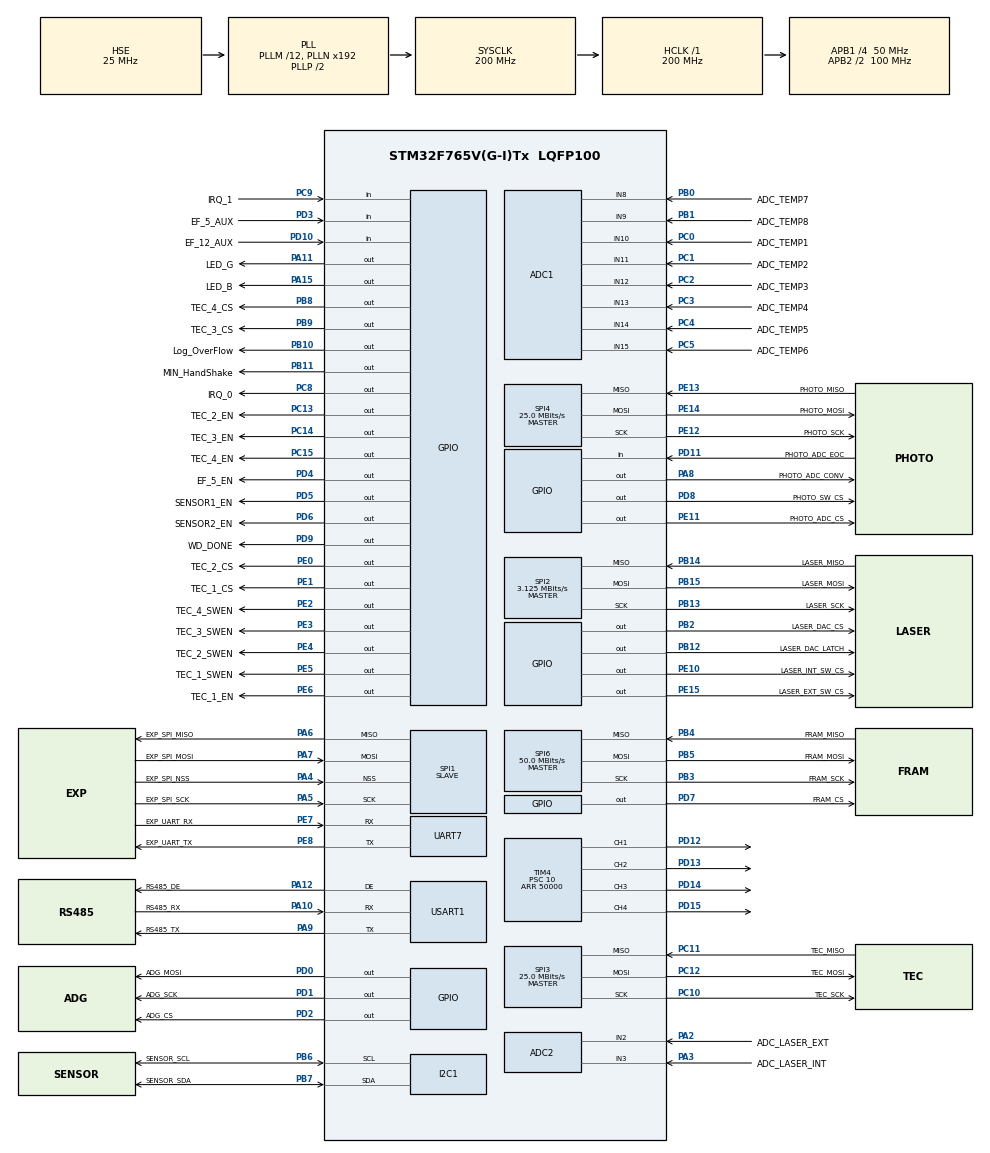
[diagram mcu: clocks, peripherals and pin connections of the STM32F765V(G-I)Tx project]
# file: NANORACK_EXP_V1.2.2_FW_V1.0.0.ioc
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ADC1.Channel-0\#ChannelRegularConversion=ADC_CHANNEL_10
ADC1.Channel-1\#ChannelRegularConversion=ADC_CHANNEL_11
ADC1.Channel-2\#ChannelRegularConversion=ADC_CHANNEL_12
ADC1.Channel-3\#ChannelRegularConversion=ADC_CHANNEL_13
ADC1.Channel-4\#ChannelRegularConversion=ADC_CHANNEL_14
ADC1.Channel-5\#ChannelRegularConversion=ADC_CHANNEL_15
ADC1.Channel-6\#ChannelRegularConversion=ADC_CHANNEL_8
ADC1.Channel-7\#ChannelRegularConversion=ADC_CHANNEL_9
ADC1.ContinuousConvMode=DISABLE
ADC1.DMAContinuousRequests=ENABLE
ADC1.EOCSelection=ADC_EOC_SEQ_CONV
ADC1.InjNumberOfConversion=0
ADC1.NbrOfConversion=8
ADC1.NbrOfConversionFlag=1
ADC1.Rank-0\#ChannelRegularConversion=1
ADC1.Rank-1\#ChannelRegularConversion=2
ADC1.Rank-2\#ChannelRegularConversion=3
ADC1.Rank-3\#ChannelRegularConversion=4
ADC1.Rank-4\#ChannelRegularConversion=5
ADC1.Rank-5\#ChannelRegularConversion=6
ADC1.Rank-6\#ChannelRegularConversion=7
ADC1.Rank-7\#ChannelRegularConversion=8
ADC1.SamplingTime-0\#ChannelRegularConversion=ADC_SAMPLETIME_15CYCLES
ADC1.SamplingTime-1\#ChannelRegularConversion=ADC_SAMPLETIME_15CYCLES
ADC1.SamplingTime-2\#ChannelRegularConversion=ADC_SAMPLETIME_15CYCLES
ADC1.SamplingTime-3\#ChannelRegularConversion=ADC_SAMPLETIME_15CYCLES
ADC1.SamplingTime-4\#ChannelRegularConversion=ADC_SAMPLETIME_15CYCLES
ADC1.SamplingTime-5\#ChannelRegularConversion=ADC_SAMPLETIME_15CYCLES
ADC1.SamplingTime-6\#ChannelRegularConversion=ADC_SAMPLETIME_15CYCLES
ADC1.SamplingTime-7\#ChannelRegularConversion=ADC_SAMPLETIME_15CYCLES
ADC1.master=1
ADC2.Channel-0\#ChannelRegularConversion=ADC_CHANNEL_3
ADC2.Channel-1\#ChannelRegularConversion=ADC_CHANNEL_2
ADC2.DMAContinuousRequests=ENABLE
ADC2.NbrOfConversion=2
ADC2.NbrOfConversionFlag=1
ADC2.Rank-0\#ChannelRegularConversion=1
ADC2.Rank-1\#ChannelRegularConversion=2
ADC2.SamplingTime-0\#ChannelRegularConversion=ADC_SAMPLETIME_15CYCLES
ADC2.SamplingTime-1\#ChannelRegularConversion=ADC_SAMPLETIME_3CYCLES
ADC2.ScanConvMode=ADC_SCAN_ENABLE
CORTEX_M7.MPU_Control=__NULL
CORTEX_M7.default_mode_Activation=1
Dma.ADC1.0.Direction=DMA_PERIPH_TO_MEMORY
Dma.ADC1.0.FIFOMode=DMA_FIFOMODE_DISABLE
Dma.ADC1.0.Instance=DMA2_Stream4
Dma.ADC1.0.MemDataAlignment=DMA_MDATAALIGN_HALFWORD
Dma.ADC1.0.MemInc=DMA_MINC_ENABLE
Dma.ADC1.0.Mode=DMA_CIRCULAR
Dma.ADC1.0.PeriphDataAlignment=DMA_PDATAALIGN_HALFWORD
Dma.ADC1.0.PeriphInc=DMA_PINC_DISABLE
Dma.ADC1.0.Priority=DMA_PRIORITY_LOW
Dma.ADC2.3.Direction=DMA_PERIPH_TO_MEMORY
Dma.ADC2.3.FIFOMode=DMA_FIFOMODE_DISABLE
Dma.ADC2.3.Instance=DMA2_Stream2
Dma.ADC2.3.MemDataAlignment=DMA_MDATAALIGN_HALFWORD
Dma.ADC2.3.MemInc=DMA_MINC_ENABLE
Dma.ADC2.3.Mode=DMA_CIRCULAR
Dma.ADC2.3.PeriphDataAlignment=DMA_PDATAALIGN_HALFWORD
Dma.ADC2.3.PeriphInc=DMA_PINC_DISABLE
Dma.ADC2.3.Priority=DMA_PRIORITY_LOW
Dma.Request0=ADC1
Dma.Request1=SPI6_TX
Dma.Request2=SPI6_RX
Dma.Request3=ADC2
Dma.Request4=SPI1_TX
Dma.Request5=SPI4_RX
Dma.SPI1_TX.4.Direction=DMA_MEMORY_TO_PERIPH
Dma.SPI1_TX.4.FIFOMode=DMA_FIFOMODE_DISABLE
Dma.SPI1_TX.4.Instance=DMA2_Stream3
Dma.SPI1_TX.4.MemDataAlignment=DMA_MDATAALIGN_BYTE
Dma.SPI1_TX.4.MemInc=DMA_MINC_ENABLE
Dma.SPI1_TX.4.Mode=DMA_NORMAL
Dma.SPI1_TX.4.PeriphDataAlignment=DMA_PDATAALIGN_BYTE
Dma.SPI1_TX.4.PeriphInc=DMA_PINC_DISABLE
Dma.SPI1_TX.4.Priority=DMA_PRIORITY_HIGH
Dma.SPI4_RX.5.Direction=DMA_PERIPH_TO_MEMORY
Dma.SPI4_RX.5.FIFOMode=DMA_FIFOMODE_DISABLE
Dma.SPI4_RX.5.Instance=DMA2_Stream0
Dma.SPI4_RX.5.MemDataAlignment=DMA_MDATAALIGN_HALFWORD
Dma.SPI4_RX.5.MemInc=DMA_MINC_ENABLE
Dma.SPI4_RX.5.Mode=DMA_CIRCULAR
Dma.SPI4_RX.5.PeriphDataAlignment=DMA_PDATAALIGN_HALFWORD
Dma.SPI4_RX.5.PeriphInc=DMA_PINC_DISABLE
Dma.SPI4_RX.5.Priority=DMA_PRIORITY_VERY_HIGH
Dma.SPI6_RX.2.Direction=DMA_PERIPH_TO_MEMORY
Dma.SPI6_RX.2.FIFOMode=DMA_FIFOMODE_DISABLE
Dma.SPI6_RX.2.Instance=DMA2_Stream6
Dma.SPI6_RX.2.MemDataAlignment=DMA_MDATAALIGN_BYTE
Dma.SPI6_RX.2.MemInc=DMA_MINC_ENABLE
Dma.SPI6_RX.2.Mode=DMA_NORMAL
Dma.SPI6_RX.2.PeriphDataAlignment=DMA_PDATAALIGN_BYTE
Dma.SPI6_RX.2.PeriphInc=DMA_PINC_DISABLE
Dma.SPI6_RX.2.Priority=DMA_PRIORITY_VERY_HIGH
Dma.SPI6_TX.1.Direction=DMA_MEMORY_TO_PERIPH
Dma.SPI6_TX.1.FIFOMode=DMA_FIFOMODE_DISABLE
Dma.SPI6_TX.1.Instance=DMA2_Stream5
Dma.SPI6_TX.1.MemDataAlignment=DMA_MDATAALIGN_BYTE
Dma.SPI6_TX.1.MemInc=DMA_MINC_ENABLE
Dma.SPI6_TX.1.Mode=DMA_NORMAL
Dma.SPI6_TX.1.PeriphDataAlignment=DMA_PDATAALIGN_BYTE
Dma.SPI6_TX.1.PeriphInc=DMA_PINC_DISABLE
Dma.SPI6_TX.1.Priority=DMA_PRIORITY_VERY_HIGH
I2C1.Speed=20
I2C1.Timing=0x601063FF
IWDG.Prescaler=IWDG_PRESCALER_128
IWDG.Reload=4000
IWDG.Window=4000
Mcu.Family=STM32F7
Mcu.Name=STM32F765V(G-I)Tx
Mcu.Package=LQFP100
NVIC.DMA2_Stream0_IRQn=true\:1\:0\:true\:false\:true\:false\:true\:true
NVIC.DMA2_Stream2_IRQn=true\:10\:0\:true\:false\:true\:false\:true\:true
NVIC.DMA2_Stream3_IRQn=true\:1\:0\:true\:false\:false\:false\:true\:true
NVIC.DMA2_Stream4_IRQn=true\:10\:0\:false\:false\:true\:false\:true\:true
NVIC.DMA2_Stream5_IRQn=true\:9\:0\:true\:false\:false\:false\:true\:true
NVIC.DMA2_Stream6_IRQn=true\:9\:0\:true\:false\:false\:false\:true\:true
NVIC.PriorityGroup=NVIC_PRIORITYGROUP_4
NVIC.TIM1_UP_TIM10_IRQn=true\:0\:0\:false\:false\:false\:true\:true\:true
NVIC.TIM2_IRQn=true\:2\:0\:true\:false\:false\:true\:true\:true
NVIC.UART7_IRQn=true\:11\:0\:true\:false\:false\:true\:true\:true
PA0/WKUP.Mode=SYS_WakeUp0
PA0/WKUP.Signal=SYS_WKUP1
PA1.GPIO_Label=ADC_TEC_OUT
PA1.Signal=ADCx_IN1
PA10.GPIO_Label=RS485_RX
PA10.Mode=Asynchronous
PA10.Signal=USART1_RX
PA11.GPIO_Label=LED_G
PA11.Signal=GPIO_Output
PA12.GPIO_Label=RS485_DE
PA12.Mode=Hardware Flow Control (RS485)
PA12.Signal=USART1_DE
PA13.Mode=Serial_Wire
PA13.Signal=SYS_JTMS-SWDIO
PA14.Mode=Serial_Wire
PA14.Signal=SYS_JTCK-SWCLK
PA15.GPIO_Label=LED_B
PA15.Signal=GPIO_Output
PA2.GPIO_Label=ADC_LASER_EXT
PA2.Signal=ADCx_IN2
PA3.GPIO_Label=ADC_LASER_INT
PA3.Signal=ADCx_IN3
PA4.GPIO_Label=EXP_SPI_NSS
PA4.Mode=NSS_Signal_Hard_Input
PA4.Signal=SPI1_NSS
PA5.GPIO_Label=EXP_SPI_SCK
PA5.Mode=Full_Duplex_Slave
PA5.Signal=SPI1_SCK
PA6.GPIO_Label=EXP_SPI_MISO
PA6.Mode=Full_Duplex_Slave
PA6.Signal=SPI1_MISO
PA7.GPIO_Label=EXP_SPI_MOSI
PA7.Mode=Full_Duplex_Slave
PA7.Signal=SPI1_MOSI
PA8.GPIO_Label=PHOTO_ADC_CONV
PA8.GPIO_Speed=GPIO_SPEED_FREQ_VERY_HIGH
PA8.PinState=GPIO_PIN_SET
PA8.Signal=GPIO_Output
PA9.GPIO_Label=RS485_TX
PA9.Mode=Asynchronous
PA9.Signal=USART1_TX
PB0.GPIO_Label=ADC_TEMP7
PB0.Signal=ADCx_IN8
PB1.GPIO_Label=ADC_TEMP8
PB1.Signal=ADCx_IN9
PB10.GPIO_Label=Log_OverFlow
PB10.GPIO_PuPd=GPIO_PULLUP
PB10.PinState=GPIO_PIN_SET
PB10.Signal=GPIO_Output
PB11.GPIO_Label=MIN_HandShake
PB11.GPIO_PuPd=GPIO_PULLDOWN
PB11.Signal=GPIO_Output
PB12.GPIO_Label=LASER_DAC_LATCH
PB12.PinState=GPIO_PIN_SET
PB12.Signal=GPIO_Output
PB13.GPIO_Label=LASER_SCK
PB13.Mode=Full_Duplex_Master
PB13.Signal=SPI2_SCK
PB14.GPIO_Label=LASER_MISO
PB14.Mode=Full_Duplex_Master
PB14.Signal=SPI2_MISO
PB15.GPIO_Label=LASER_MOSI
PB15.Mode=Full_Duplex_Master
PB15.Signal=SPI2_MOSI
PB2.GPIO_Label=LASER_DAC_CS
PB2.PinState=GPIO_PIN_SET
PB2.Signal=GPIO_Output
PB3.GPIO_Label=FRAM_SCK
PB3.Mode=Full_Duplex_Master
PB3.Signal=SPI6_SCK
PB4.GPIO_Label=FRAM_MISO
PB4.Mode=Full_Duplex_Master
PB4.Signal=SPI6_MISO
PB5.GPIO_Label=FRAM_MOSI
PB5.Mode=Full_Duplex_Master
PB5.Signal=SPI6_MOSI
PB6.GPIO_Label=SENSOR_SCL
PB6.Mode=I2C
PB6.Signal=I2C1_SCL
PB7.GPIO_Label=SENSOR_SDA
PB7.Mode=I2C
PB7.Signal=I2C1_SDA
PB8.GPIO_Label=TEC_4_CS
PB8.PinState=GPIO_PIN_SET
PB8.Signal=GPIO_Output
PB9.GPIO_Label=TEC_3_CS
PB9.PinState=GPIO_PIN_SET
PB9.Signal=GPIO_Output
PC0.GPIO_Label=ADC_TEMP1
PC0.Signal=ADCx_IN10
PC1.GPIO_Label=ADC_TEMP2
PC1.Signal=ADCx_IN11
PC10.GPIO_Label=TEC_SCK
PC10.Mode=Full_Duplex_Master
PC10.Signal=SPI3_SCK
PC11.GPIO_Label=TEC_MISO
PC11.Mode=Full_Duplex_Master
PC11.Signal=SPI3_MISO
PC12.GPIO_Label=TEC_MOSI
PC12.Mode=Full_Duplex_Master
PC12.Signal=SPI3_MOSI
PC13.GPIO_Label=TEC_2_EN
PC13.Signal=GPIO_Output
PC14/OSC32_IN.GPIO_Label=TEC_3_EN
PC14/OSC32_IN.Signal=GPIO_Output
PC15/OSC32_OUT.GPIO_Label=TEC_4_EN
PC15/OSC32_OUT.Signal=GPIO_Output
PC2.GPIO_Label=ADC_TEMP3
PC2.Signal=ADCx_IN12
PC3.GPIO_Label=ADC_TEMP4
PC3.Signal=ADCx_IN13
PC4.GPIO_Label=ADC_TEMP5
PC4.Signal=ADCx_IN14
PC5.GPIO_Label=ADC_TEMP6
PC5.Signal=ADCx_IN15
PC6.GPIO_Label=CONS_TX
PC6.Signal=USART6_TX
PC7.GPIO_Label=CONS_RX
PC7.Signal=USART6_RX
PC8.GPIO_Label=IRQ_0
PC8.GPIO_PuPd=GPIO_PULLUP
PC8.PinState=GPIO_PIN_SET
PC8.Signal=GPIO_Output
PC9.GPIO_Label=IRQ_1
PC9.Signal=GPIO_Input
PD0.GPIO_Label=ADG_MOSI
PD0.Signal=GPIO_Output
PD1.GPIO_Label=ADG_SCK
PD1.Signal=GPIO_Output
PD10.GPIO_Label=EF_12_AUX
PD10.Signal=GPIO_Input
PD11.GPIO_Label=PHOTO_ADC_EOC
PD11.Signal=GPIO_Input
PD12.Signal=S_TIM4_CH1
PD13.Signal=S_TIM4_CH2
PD14.Signal=S_TIM4_CH3
PD15.Signal=S_TIM4_CH4
PD2.GPIO_Label=ADG_CS
PD2.PinState=GPIO_PIN_SET
PD2.Signal=GPIO_Output
PD3.GPIO_Label=EF_5_AUX
PD3.Signal=GPIO_Input
PD4.GPIO_Label=EF_5_EN
PD4.Signal=GPIO_Output
PD5.GPIO_Label=SENSOR1_EN
PD5.Signal=GPIO_Output
PD6.GPIO_Label=SENSOR2_EN
PD6.Signal=GPIO_Output
PD7.GPIO_Label=FRAM_CS
PD7.PinState=GPIO_PIN_SET
PD7.Signal=GPIO_Output
PD8.GPIO_Label=PHOTO_SW_CS
PD8.GPIO_Speed=GPIO_SPEED_FREQ_VERY_HIGH
PD8.PinState=GPIO_PIN_SET
PD8.Signal=GPIO_Output
PD9.GPIO_Label=WD_DONE
PD9.GPIO_Speed=GPIO_SPEED_FREQ_VERY_HIGH
PD9.PinState=GPIO_PIN_SET
PD9.Signal=GPIO_Output
PE0.GPIO_Label=TEC_2_CS
PE0.PinState=GPIO_PIN_SET
PE0.Signal=GPIO_Output
PE1.GPIO_Label=TEC_1_CS
PE1.PinState=GPIO_PIN_SET
PE1.Signal=GPIO_Output
PE10.GPIO_Label=LASER_INT_SW_CS
PE10.PinState=GPIO_PIN_SET
PE10.Signal=GPIO_Output
PE11.GPIO_Label=PHOTO_ADC_CS
PE11.GPIO_Speed=GPIO_SPEED_FREQ_LOW
PE11.PinState=GPIO_PIN_SET
PE11.Signal=GPIO_Output
PE12.GPIO_Label=PHOTO_SCK
PE12.Mode=Full_Duplex_Master
PE12.Signal=SPI4_SCK
PE13.GPIO_Label=PHOTO_MISO
PE13.Mode=Full_Duplex_Master
PE13.Signal=SPI4_MISO
PE14.GPIO_Label=PHOTO_MOSI
PE14.Mode=Full_Duplex_Master
PE14.Signal=SPI4_MOSI
PE15.GPIO_Label=LASER_EXT_SW_CS
PE15.PinState=GPIO_PIN_SET
PE15.Signal=GPIO_Output
PE2.GPIO_Label=TEC_4_SWEN
PE2.Signal=GPIO_Output
PE3.GPIO_Label=TEC_3_SWEN
PE3.Signal=GPIO_Output
PE4.GPIO_Label=TEC_2_SWEN
PE4.Signal=GPIO_Output
PE5.GPIO_Label=TEC_1_SWEN
PE5.Signal=GPIO_Output
PE6.GPIO_Label=TEC_1_EN
PE6.Signal=GPIO_Output
PE7.GPIO_Label=EXP_UART_RX
PE7.GPIO_PuPd=GPIO_PULLUP
PE7.Mode=Asynchronous
PE7.Signal=UART7_RX
PE8.GPIO_Label=EXP_UART_TX
PE8.Mode=Asynchronous
PE8.Signal=UART7_TX
PH0/OSC_IN.Mode=HSE-External-Oscillator
PH0/OSC_IN.Signal=RCC_OSC_IN
PH1/OSC_OUT.Mode=HSE-External-Oscillator
PH1/OSC_OUT.Signal=RCC_OSC_OUT
ProjectManager.HeapSize=0x200
ProjectManager.StackSize=0x400
ProjectManager.TargetToolchain=STM32CubeIDE
RCC.AHBFreq_Value=200000000
RCC.APB1CLKDivider=RCC_HCLK_DIV4
RCC.APB1Freq_Value=50000000
RCC.APB1TimFreq_Value=100000000
RCC.APB2CLKDivider=RCC_HCLK_DIV2
RCC.APB2Freq_Value=100000000
RCC.APB2TimFreq_Value=200000000
RCC.CortexFreq_Value=200000000
RCC.HCLKFreq_Value=200000000
RCC.HSE_VALUE=25000000
RCC.HSI_VALUE=16000000
RCC.LSE_VALUE=32768
RCC.PLLM=12
RCC.PLLSourceVirtual=RCC_PLLSOURCE_HSE
RCC.SYSCLKFreq_VALUE=200000000
RCC.SYSCLKSource=RCC_SYSCLKSOURCE_PLLCLK
RCC.USBFreq_Value=200000000
RCC.VCOOutputFreq_Value=400000000
SH.ADCx_IN1.0=ADC3_IN1
SH.ADCx_IN10.0=ADC1_IN10,IN10
SH.ADCx_IN11.0=ADC1_IN11,IN11
SH.ADCx_IN12.0=ADC1_IN12,IN12
SH.ADCx_IN13.0=ADC1_IN13,IN13
SH.ADCx_IN14.0=ADC1_IN14,IN14
SH.ADCx_IN15.0=ADC1_IN15,IN15
SH.ADCx_IN2.0=ADC2_IN2,IN2
SH.ADCx_IN3.0=ADC2_IN3,IN3
SH.ADCx_IN8.0=ADC1_IN8,IN8
SH.ADCx_IN9.0=ADC1_IN9,IN9
SH.S_TIM4_CH1.0=TIM4_CH1,PWM Generation1 CH1
SH.S_TIM4_CH2.0=TIM4_CH2,PWM Generation2 CH2
SH.S_TIM4_CH3.0=TIM4_CH3,PWM Generation3 CH3
SH.S_TIM4_CH4.0=TIM4_CH4,PWM Generation4 CH4
SPI1.CLKPolarity=SPI_POLARITY_HIGH
SPI1.DataSize=SPI_DATASIZE_8BIT
SPI1.Direction=SPI_DIRECTION_2LINES
SPI1.Mode=SPI_MODE_SLAVE
SPI1.VirtualNSS=VM_NSSHARD
SPI1.VirtualType=VM_SLAVE
SPI2.BaudRatePrescaler=SPI_BAUDRATEPRESCALER_16
SPI2.CLKPhase=SPI_PHASE_2EDGE
SPI2.CalculateBaudRate=3.125 MBits/s
SPI2.DataSize=SPI_DATASIZE_8BIT
SPI2.Direction=SPI_DIRECTION_2LINES
SPI2.Mode=SPI_MODE_MASTER
SPI2.VirtualType=VM_MASTER
SPI3.BaudRatePrescaler=SPI_BAUDRATEPRESCALER_2
SPI3.CalculateBaudRate=25.0 MBits/s
SPI3.DataSize=SPI_DATASIZE_8BIT
SPI3.Direction=SPI_DIRECTION_2LINES
SPI3.Mode=SPI_MODE_MASTER
SPI3.VirtualType=VM_MASTER
SPI4.BaudRatePrescaler=SPI_BAUDRATEPRESCALER_4
SPI4.CLKPhase=SPI_PHASE_1EDGE
SPI4.CalculateBaudRate=25.0 MBits/s
SPI4.DataSize=SPI_DATASIZE_16BIT
SPI4.Direction=SPI_DIRECTION_2LINES
SPI4.Mode=SPI_MODE_MASTER
SPI4.VirtualType=VM_MASTER
SPI6.BaudRatePrescaler=SPI_BAUDRATEPRESCALER_2
SPI6.CalculateBaudRate=50.0 MBits/s
SPI6.DataSize=SPI_DATASIZE_8BIT
SPI6.Direction=SPI_DIRECTION_2LINES
SPI6.Mode=SPI_MODE_MASTER
SPI6.VirtualType=VM_MASTER
TIM1.Prescaler=0
TIM2.AutoReloadPreload=TIM_AUTORELOAD_PRELOAD_ENABLE
TIM4.Channel-PWM\ Generation1\ CH1=TIM_CHANNEL_1
TIM4.Channel-PWM\ Generation2\ CH2=TIM_CHANNEL_2
TIM4.Channel-PWM\ Generation3\ CH3=TIM_CHANNEL_3
TIM4.Channel-PWM\ Generation4\ CH4=TIM_CHANNEL_4
TIM4.ClockDivision=TIM_CLOCKDIVISION_DIV4
TIM4.Period=50000
TIM4.Prescaler=10
USART1.VirtualMode-Asynchronous=VM_ASYNC
USART1.VirtualMode-Hardware\ Flow\ Control\ (RS485)=VM_ASYNC
VP_CRC_VS_CRC.Mode=CRC_Activate
VP_IWDG_VS_IWDG.Mode=IWDG_Activate
VP_TIM1_VS_ClockSourceINT.Mode=Internal
VP_TIM2_VS_ClockSourceINT.Mode=Internal
VP_TIM4_VS_ClockSourceINT.Mode=Internal
board=custom

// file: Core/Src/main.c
/* USER CODE BEGIN Header */
/**
  ******************************************************************************
  * @file           : main.c
  * @brief          : Main program body
  ******************************************************************************
  * @attention
  *
  * Copyright (c) 2025 STMicroelectronics.
  * All rights reserved.
  *
  * This software is licensed under terms that can be found in the LICENSE file
  * in the root directory of this software component.
  * If no LICENSE file comes with this software, it is provided AS-IS.
  *
  ******************************************************************************
  */
/* USER CODE END Header */
#include "main.h"

/* USER CODE BEGIN Includes */
#include "board.h"
#include "uart_driver.h"
#include "ntc.h"
#include "cli_command.h"
#include "sensor_i2c.h"
#include "adg1414.h"
#include "ads8327.h"
#include "mcp4902.h"
#include "app_main.h"
#include "bsp_photodiode.h"
#include "bsp_spi_ram.h"
#include "IS66WVS4M8BLL.h"
/* USER CODE END Includes */

CRC_HandleTypeDef hcrc;

void SystemClock_Config(void);
static void MX_GPIO_Init(void);
static void MX_DMA_Init(void);
static void MX_I2C1_Init(void);
static void MX_SPI1_Init(void);
static void MX_SPI2_Init(void);
static void MX_SPI3_Init(void);
static void MX_ADC1_Init(void);
static void MX_SPI4_Init(void);
static void MX_TIM4_Init(void);
static void MX_UART7_Init(void);
static void MX_SPI6_Init(void);
static void MX_USART1_UART_Init(void);
static void MX_ADC2_Init(void);
static void MX_TIM1_Init(void);
static void MX_TIM2_Init(void);
static void MX_IWDG_Init(void);
static void MX_CRC_Init(void);
/* USER CODE BEGIN PFP */
void SPI1_ReInit(void)
{
	MX_SPI1_Init();
}
/* USER CODE END PFP */

int main(void)
{

  /* MCU Configuration--------------------------------------------------------*/

  /* Reset of all peripherals, Initializes the Flash interface and the Systick. */
  HAL_Init();

  /* Configure the system clock */
  SystemClock_Config();

  /* Initialize all configured peripherals */
  MX_GPIO_Init();
  MX_DMA_Init();
  MX_I2C1_Init();
  MX_SPI1_Init();
  MX_SPI2_Init();
  MX_SPI3_Init();
  MX_ADC1_Init();
  MX_SPI4_Init();
  MX_TIM4_Init();
  MX_UART7_Init();
  MX_SPI6_Init();
  MX_USART1_UART_Init();
  MX_ADC2_Init();
  MX_TIM1_Init();
  MX_TIM2_Init();
  MX_IWDG_Init();
  MX_CRC_Init();

  /* Infinite loop */
  /* USER CODE BEGIN WHILE */

  app_init();
  app_start();
  app_run();
  while (1)
  {
    /* USER CODE END WHILE */

  }
}

void SystemClock_Config(void)
{
  RCC_OscInitTypeDef RCC_OscInitStruct = {0};
  RCC_ClkInitTypeDef RCC_ClkInitStruct = {0};

  /** Configure the main internal regulator output voltage
  */
  __HAL_RCC_PWR_CLK_ENABLE();
  __HAL_PWR_VOLTAGESCALING_CONFIG(PWR_REGULATOR_VOLTAGE_SCALE1);

  /** Initializes the RCC Oscillators according to the specified parameters
  * in the RCC_OscInitTypeDef structure.
  */
  RCC_OscInitStruct.OscillatorType = RCC_OSCILLATORTYPE_LSI|RCC_OSCILLATORTYPE_HSE;
  RCC_OscInitStruct.HSEState = RCC_HSE_ON;
  RCC_OscInitStruct.LSIState = RCC_LSI_ON;
  RCC_OscInitStruct.PLL.PLLState = RCC_PLL_ON;
  RCC_OscInitStruct.PLL.PLLSource = RCC_PLLSOURCE_HSE;
  RCC_OscInitStruct.PLL.PLLM = 12;
  RCC_OscInitStruct.PLL.PLLN = 192;
  RCC_OscInitStruct.PLL.PLLP = RCC_PLLP_DIV2;
  RCC_OscInitStruct.PLL.PLLQ = 2;
  RCC_OscInitStruct.PLL.PLLR = 2;
  if (HAL_RCC_OscConfig(&RCC_OscInitStruct) != HAL_OK)
  {
    Error_Handler();
  }

  /** Activate the Over-Drive mode
  */
  if (HAL_PWREx_EnableOverDrive() != HAL_OK)
  {
    Error_Handler();
  }

  /** Initializes the CPU, AHB and APB buses clocks
  */
  RCC_ClkInitStruct.ClockType = RCC_CLOCKTYPE_HCLK|RCC_CLOCKTYPE_SYSCLK
                              |RCC_CLOCKTYPE_PCLK1|RCC_CLOCKTYPE_PCLK2;
  RCC_ClkInitStruct.SYSCLKSource = RCC_SYSCLKSOURCE_PLLCLK;
  RCC_ClkInitStruct.AHBCLKDivider = RCC_SYSCLK_DIV1;
  RCC_ClkInitStruct.APB1CLKDivider = RCC_HCLK_DIV4;
  RCC_ClkInitStruct.APB2CLKDivider = RCC_HCLK_DIV2;

  if (HAL_RCC_ClockConfig(&RCC_ClkInitStruct, FLASH_LATENCY_6) != HAL_OK)
  {
    Error_Handler();
  }
}

static void MX_ADC1_Init(void)
{

  LL_ADC_InitTypeDef ADC_InitStruct = {0};
  LL_ADC_REG_InitTypeDef ADC_REG_InitStruct = {0};
  LL_ADC_CommonInitTypeDef ADC_CommonInitStruct = {0};

  LL_GPIO_InitTypeDef GPIO_InitStruct = {0};

  /* Peripheral clock enable */
  LL_APB2_GRP1_EnableClock(LL_APB2_GRP1_PERIPH_ADC1);

  LL_AHB1_GRP1_EnableClock(LL_AHB1_GRP1_PERIPH_GPIOC);
  LL_AHB1_GRP1_EnableClock(LL_AHB1_GRP1_PERIPH_GPIOB);
  /**ADC1 GPIO Configuration
  PC0   ------> ADC1_IN10
  PC1   ------> ADC1_IN11
  PC2   ------> ADC1_IN12
  PC3   ------> ADC1_IN13
  PC4   ------> ADC1_IN14
  PC5   ------> ADC1_IN15
  PB0   ------> ADC1_IN8
  PB1   ------> ADC1_IN9
  */
  GPIO_InitStruct.Pin = ADC_TEMP1_Pin;
  GPIO_InitStruct.Mode = LL_GPIO_MODE_ANALOG;
  GPIO_InitStruct.Pull = LL_GPIO_PULL_NO;
  LL_GPIO_Init(ADC_TEMP1_GPIO_Port, &GPIO_InitStruct);

  GPIO_InitStruct.Pin = ADC_TEMP2_Pin;
  GPIO_InitStruct.Mode = LL_GPIO_MODE_ANALOG;
  GPIO_InitStruct.Pull = LL_GPIO_PULL_NO;
  LL_GPIO_Init(ADC_TEMP2_GPIO_Port, &GPIO_InitStruct);

  GPIO_InitStruct.Pin = ADC_TEMP3_Pin;
  GPIO_InitStruct.Mode = LL_GPIO_MODE_ANALOG;
  GPIO_InitStruct.Pull = LL_GPIO_PULL_NO;
  LL_GPIO_Init(ADC_TEMP3_GPIO_Port, &GPIO_InitStruct);

  GPIO_InitStruct.Pin = ADC_TEMP4_Pin;
  GPIO_InitStruct.Mode = LL_GPIO_MODE_ANALOG;
  GPIO_InitStruct.Pull = LL_GPIO_PULL_NO;
  LL_GPIO_Init(ADC_TEMP4_GPIO_Port, &GPIO_InitStruct);

  GPIO_InitStruct.Pin = ADC_TEMP5_Pin;
  GPIO_InitStruct.Mode = LL_GPIO_MODE_ANALOG;
  GPIO_InitStruct.Pull = LL_GPIO_PULL_NO;
  LL_GPIO_Init(ADC_TEMP5_GPIO_Port, &GPIO_InitStruct);

  GPIO_InitStruct.Pin = ADC_TEMP6_Pin;
  GPIO_InitStruct.Mode = LL_GPIO_MODE_ANALOG;
  GPIO_InitStruct.Pull = LL_GPIO_PULL_NO;
  LL_GPIO_Init(ADC_TEMP6_GPIO_Port, &GPIO_InitStruct);

  GPIO_InitStruct.Pin = ADC_TEMP7_Pin;
  GPIO_InitStruct.Mode = LL_GPIO_MODE_ANALOG;
  GPIO_InitStruct.Pull = LL_GPIO_PULL_NO;
  LL_GPIO_Init(ADC_TEMP7_GPIO_Port, &GPIO_InitStruct);

  GPIO_InitStruct.Pin = ADC_TEMP8_Pin;
  GPIO_InitStruct.Mode = LL_GPIO_MODE_ANALOG;
  GPIO_InitStruct.Pull = LL_GPIO_PULL_NO;
  LL_GPIO_Init(ADC_TEMP8_GPIO_Port, &GPIO_InitStruct);

  /* ADC1 DMA Init */

  /* ADC1 Init */
  LL_DMA_SetChannelSelection(DMA2, LL_DMA_STREAM_4, LL_DMA_CHANNEL_0);

  LL_DMA_SetDataTransferDirection(DMA2, LL_DMA_STREAM_4, LL_DMA_DIRECTION_PERIPH_TO_MEMORY);

  LL_DMA_SetStreamPriorityLevel(DMA2, LL_DMA_STREAM_4, LL_DMA_PRIORITY_LOW);

  LL_DMA_SetMode(DMA2, LL_DMA_STREAM_4, LL_DMA_MODE_CIRCULAR);

  LL_DMA_SetPeriphIncMode(DMA2, LL_DMA_STREAM_4, LL_DMA_PERIPH_NOINCREMENT);

  LL_DMA_SetMemoryIncMode(DMA2, LL_DMA_STREAM_4, LL_DMA_MEMORY_INCREMENT);

  LL_DMA_SetPeriphSize(DMA2, LL_DMA_STREAM_4, LL_DMA_PDATAALIGN_HALFWORD);

  LL_DMA_SetMemorySize(DMA2, LL_DMA_STREAM_4, LL_DMA_MDATAALIGN_HALFWORD);

  LL_DMA_DisableFifoMode(DMA2, LL_DMA_STREAM_4);

  /** Common config
  */
  ADC_InitStruct.Resolution = LL_ADC_RESOLUTION_12B;
  ADC_InitStruct.DataAlignment = LL_ADC_DATA_ALIGN_RIGHT;
  ADC_InitStruct.SequencersScanMode = LL_ADC_SEQ_SCAN_ENABLE;
  LL_ADC_Init(ADC1, &ADC_InitStruct);
  ADC_REG_InitStruct.TriggerSource = LL_ADC_REG_TRIG_SOFTWARE;
  ADC_REG_InitStruct.SequencerLength = LL_ADC_REG_SEQ_SCAN_ENABLE_8RANKS;
  ADC_REG_InitStruct.SequencerDiscont = LL_ADC_REG_SEQ_DISCONT_DISABLE;
  ADC_REG_InitStruct.ContinuousMode = LL_ADC_REG_CONV_SINGLE;
  ADC_REG_InitStruct.DMATransfer = LL_ADC_REG_DMA_TRANSFER_UNLIMITED;
  LL_ADC_REG_Init(ADC1, &ADC_REG_InitStruct);
  LL_ADC_REG_SetFlagEndOfConversion(ADC1, LL_ADC_REG_FLAG_EOC_SEQUENCE_CONV);
  ADC_CommonInitStruct.CommonClock = LL_ADC_CLOCK_SYNC_PCLK_DIV4;
  ADC_CommonInitStruct.Multimode = LL_ADC_MULTI_INDEPENDENT;
  LL_ADC_CommonInit(__LL_ADC_COMMON_INSTANCE(ADC1), &ADC_CommonInitStruct);

  /** Configure Regular Channel
  */
  LL_ADC_REG_SetSequencerRanks(ADC1, LL_ADC_REG_RANK_1, LL_ADC_CHANNEL_10);
  LL_ADC_SetChannelSamplingTime(ADC1, LL_ADC_CHANNEL_10, LL_ADC_SAMPLINGTIME_15CYCLES);

  /** Configure Regular Channel
  */
  LL_ADC_REG_SetSequencerRanks(ADC1, LL_ADC_REG_RANK_2, LL_ADC_CHANNEL_11);
  LL_ADC_SetChannelSamplingTime(ADC1, LL_ADC_CHANNEL_11, LL_ADC_SAMPLINGTIME_15CYCLES);

  /** Configure Regular Channel
  */
  LL_ADC_REG_SetSequencerRanks(ADC1, LL_ADC_REG_RANK_3, LL_ADC_CHANNEL_12);
  LL_ADC_SetChannelSamplingTime(ADC1, LL_ADC_CHANNEL_12, LL_ADC_SAMPLINGTIME_15CYCLES);

  /** Configure Regular Channel
  */
  LL_ADC_REG_SetSequencerRanks(ADC1, LL_ADC_REG_RANK_4, LL_ADC_CHANNEL_13);
  LL_ADC_SetChannelSamplingTime(ADC1, LL_ADC_CHANNEL_13, LL_ADC_SAMPLINGTIME_15CYCLES);

  /** Configure Regular Channel
  */
  LL_ADC_REG_SetSequencerRanks(ADC1, LL_ADC_REG_RANK_5, LL_ADC_CHANNEL_14);
  LL_ADC_SetChannelSamplingTime(ADC1, LL_ADC_CHANNEL_14, LL_ADC_SAMPLINGTIME_15CYCLES);

  /** Configure Regular Channel
  */
  LL_ADC_REG_SetSequencerRanks(ADC1, LL_ADC_REG_RANK_6, LL_ADC_CHANNEL_15);
  LL_ADC_SetChannelSamplingTime(ADC1, LL_ADC_CHANNEL_15, LL_ADC_SAMPLINGTIME_15CYCLES);

  /** Configure Regular Channel
  */
  LL_ADC_REG_SetSequencerRanks(ADC1, LL_ADC_REG_RANK_7, LL_ADC_CHANNEL_8);
  LL_ADC_SetChannelSamplingTime(ADC1, LL_ADC_CHANNEL_8, LL_ADC_SAMPLINGTIME_15CYCLES);

  /** Configure Regular Channel
  */
  LL_ADC_REG_SetSequencerRanks(ADC1, LL_ADC_REG_RANK_8, LL_ADC_CHANNEL_9);
  LL_ADC_SetChannelSamplingTime(ADC1, LL_ADC_CHANNEL_9, LL_ADC_SAMPLINGTIME_15CYCLES);

}

static void MX_ADC2_Init(void)
{

  LL_ADC_InitTypeDef ADC_InitStruct = {0};
  LL_ADC_REG_InitTypeDef ADC_REG_InitStruct = {0};

  LL_GPIO_InitTypeDef GPIO_InitStruct = {0};

  /* Peripheral clock enable */
  LL_APB2_GRP1_EnableClock(LL_APB2_GRP1_PERIPH_ADC2);

  LL_AHB1_GRP1_EnableClock(LL_AHB1_GRP1_PERIPH_GPIOA);
  /**ADC2 GPIO Configuration
  PA2   ------> ADC2_IN2
  PA3   ------> ADC2_IN3
  */
  GPIO_InitStruct.Pin = ADC_LASER_EXT_Pin;
  GPIO_InitStruct.Mode = LL_GPIO_MODE_ANALOG;
  GPIO_InitStruct.Pull = LL_GPIO_PULL_NO;
  LL_GPIO_Init(ADC_LASER_EXT_GPIO_Port, &GPIO_InitStruct);

  GPIO_InitStruct.Pin = ADC_LASER_INT_Pin;
  GPIO_InitStruct.Mode = LL_GPIO_MODE_ANALOG;
  GPIO_InitStruct.Pull = LL_GPIO_PULL_NO;
  LL_GPIO_Init(ADC_LASER_INT_GPIO_Port, &GPIO_InitStruct);

  /* ADC2 DMA Init */

  /* ADC2 Init */
  LL_DMA_SetChannelSelection(DMA2, LL_DMA_STREAM_2, LL_DMA_CHANNEL_1);

  LL_DMA_SetDataTransferDirection(DMA2, LL_DMA_STREAM_2, LL_DMA_DIRECTION_PERIPH_TO_MEMORY);

  LL_DMA_SetStreamPriorityLevel(DMA2, LL_DMA_STREAM_2, LL_DMA_PRIORITY_LOW);

  LL_DMA_SetMode(DMA2, LL_DMA_STREAM_2, LL_DMA_MODE_CIRCULAR);

  LL_DMA_SetPeriphIncMode(DMA2, LL_DMA_STREAM_2, LL_DMA_PERIPH_NOINCREMENT);

  LL_DMA_SetMemoryIncMode(DMA2, LL_DMA_STREAM_2, LL_DMA_MEMORY_INCREMENT);

  LL_DMA_SetPeriphSize(DMA2, LL_DMA_STREAM_2, LL_DMA_PDATAALIGN_HALFWORD);

  LL_DMA_SetMemorySize(DMA2, LL_DMA_STREAM_2, LL_DMA_MDATAALIGN_HALFWORD);

  LL_DMA_DisableFifoMode(DMA2, LL_DMA_STREAM_2);

  /** Common config
  */
  ADC_InitStruct.Resolution = LL_ADC_RESOLUTION_12B;
  ADC_InitStruct.DataAlignment = LL_ADC_DATA_ALIGN_RIGHT;
  ADC_InitStruct.SequencersScanMode = LL_ADC_SEQ_SCAN_ENABLE;
  LL_ADC_Init(ADC2, &ADC_InitStruct);
  ADC_REG_InitStruct.TriggerSource = LL_ADC_REG_TRIG_SOFTWARE;
  ADC_REG_InitStruct.SequencerLength = LL_ADC_REG_SEQ_SCAN_ENABLE_2RANKS;
  ADC_REG_InitStruct.SequencerDiscont = LL_ADC_REG_SEQ_DISCONT_DISABLE;
  ADC_REG_InitStruct.ContinuousMode = LL_ADC_REG_CONV_SINGLE;
  ADC_REG_InitStruct.DMATransfer = LL_ADC_REG_DMA_TRANSFER_UNLIMITED;
  LL_ADC_REG_Init(ADC2, &ADC_REG_InitStruct);
  LL_ADC_REG_SetFlagEndOfConversion(ADC2, LL_ADC_REG_FLAG_EOC_UNITARY_CONV);

  /** Configure Regular Channel
  */
  LL_ADC_REG_SetSequencerRanks(ADC2, LL_ADC_REG_RANK_1, LL_ADC_CHANNEL_3);
  LL_ADC_SetChannelSamplingTime(ADC2, LL_ADC_CHANNEL_3, LL_ADC_SAMPLINGTIME_15CYCLES);

  /** Configure Regular Channel
  */
  LL_ADC_REG_SetSequencerRanks(ADC2, LL_ADC_REG_RANK_2, LL_ADC_CHANNEL_2);
  LL_ADC_SetChannelSamplingTime(ADC2, LL_ADC_CHANNEL_2, LL_ADC_SAMPLINGTIME_3CYCLES);

}

static void MX_CRC_Init(void)
{

  hcrc.Instance = CRC;
  hcrc.Init.DefaultPolynomialUse = DEFAULT_POLYNOMIAL_ENABLE;
  hcrc.Init.DefaultInitValueUse = DEFAULT_INIT_VALUE_ENABLE;
  hcrc.Init.InputDataInversionMode = CRC_INPUTDATA_INVERSION_NONE;
  hcrc.Init.OutputDataInversionMode = CRC_OUTPUTDATA_INVERSION_DISABLE;
  hcrc.InputDataFormat = CRC_INPUTDATA_FORMAT_BYTES;
  if (HAL_CRC_Init(&hcrc) != HAL_OK)
  {
    Error_Handler();
  }

}

static void MX_I2C1_Init(void)
{

  LL_I2C_InitTypeDef I2C_InitStruct = {0};

  LL_GPIO_InitTypeDef GPIO_InitStruct = {0};
  RCC_PeriphCLKInitTypeDef PeriphClkInitStruct = {0};

  /** Initializes the peripherals clock
  */
  PeriphClkInitStruct.PeriphClockSelection = RCC_PERIPHCLK_I2C1;
  PeriphClkInitStruct.I2c1ClockSelection = RCC_I2C1CLKSOURCE_PCLK1;
  if (HAL_RCCEx_PeriphCLKConfig(&PeriphClkInitStruct) != HAL_OK)
  {
    Error_Handler();
  }

  LL_AHB1_GRP1_EnableClock(LL_AHB1_GRP1_PERIPH_GPIOB);
  /**I2C1 GPIO Configuration
  PB6   ------> I2C1_SCL
  PB7   ------> I2C1_SDA
  */
  GPIO_InitStruct.Pin = SENSOR_SCL_Pin;
  GPIO_InitStruct.Mode = LL_GPIO_MODE_ALTERNATE;
  GPIO_InitStruct.Speed = LL_GPIO_SPEED_FREQ_VERY_HIGH;
  GPIO_InitStruct.OutputType = LL_GPIO_OUTPUT_OPENDRAIN;
  GPIO_InitStruct.Pull = LL_GPIO_PULL_NO;
  GPIO_InitStruct.Alternate = LL_GPIO_AF_4;
  LL_GPIO_Init(SENSOR_SCL_GPIO_Port, &GPIO_InitStruct);

  GPIO_InitStruct.Pin = SENSOR_SDA_Pin;
  GPIO_InitStruct.Mode = LL_GPIO_MODE_ALTERNATE;
  GPIO_InitStruct.Speed = LL_GPIO_SPEED_FREQ_VERY_HIGH;
  GPIO_InitStruct.OutputType = LL_GPIO_OUTPUT_OPENDRAIN;
  GPIO_InitStruct.Pull = LL_GPIO_PULL_NO;
  GPIO_InitStruct.Alternate = LL_GPIO_AF_4;
  LL_GPIO_Init(SENSOR_SDA_GPIO_Port, &GPIO_InitStruct);

  /* Peripheral clock enable */
  LL_APB1_GRP1_EnableClock(LL_APB1_GRP1_PERIPH_I2C1);

  /** I2C Initialization
  */
  LL_I2C_EnableAutoEndMode(I2C1);
  LL_I2C_SetOwnAddress2(I2C1, 0, LL_I2C_OWNADDRESS2_NOMASK);
  LL_I2C_DisableOwnAddress2(I2C1);
  LL_I2C_DisableGeneralCall(I2C1);
  LL_I2C_EnableClockStretching(I2C1);
  I2C_InitStruct.PeripheralMode = LL_I2C_MODE_I2C;
  I2C_InitStruct.Timing = 0x601063FF;
  I2C_InitStruct.AnalogFilter = LL_I2C_ANALOGFILTER_ENABLE;
  I2C_InitStruct.DigitalFilter = 0;
  I2C_InitStruct.OwnAddress1 = 0;
  I2C_InitStruct.TypeAcknowledge = LL_I2C_ACK;
  I2C_InitStruct.OwnAddrSize = LL_I2C_OWNADDRESS1_7BIT;
  LL_I2C_Init(I2C1, &I2C_InitStruct);
  /* USER CODE BEGIN I2C1_Init 2 */
  LL_I2C_Enable(I2C1);
  /* USER CODE END I2C1_Init 2 */

}

static void MX_IWDG_Init(void)
{

  LL_IWDG_Enable(IWDG);
  LL_IWDG_EnableWriteAccess(IWDG);
  LL_IWDG_SetPrescaler(IWDG, LL_IWDG_PRESCALER_128);
  LL_IWDG_SetReloadCounter(IWDG, 4000);
  while (LL_IWDG_IsReady(IWDG) != 1)
  {
  }

  LL_IWDG_SetWindow(IWDG, 4000);

}

static void MX_SPI1_Init(void)
{

  LL_SPI_InitTypeDef SPI_InitStruct = {0};

  LL_GPIO_InitTypeDef GPIO_InitStruct = {0};

  /* Peripheral clock enable */
  LL_APB2_GRP1_EnableClock(LL_APB2_GRP1_PERIPH_SPI1);

  LL_AHB1_GRP1_EnableClock(LL_AHB1_GRP1_PERIPH_GPIOA);
  /**SPI1 GPIO Configuration
  PA4   ------> SPI1_NSS
  PA5   ------> SPI1_SCK
  PA6   ------> SPI1_MISO
  PA7   ------> SPI1_MOSI
  */
  GPIO_InitStruct.Pin = EXP_SPI_NSS_Pin;
  GPIO_InitStruct.Mode = LL_GPIO_MODE_ALTERNATE;
  GPIO_InitStruct.Speed = LL_GPIO_SPEED_FREQ_VERY_HIGH;
  GPIO_InitStruct.OutputType = LL_GPIO_OUTPUT_PUSHPULL;
  GPIO_InitStruct.Pull = LL_GPIO_PULL_NO;
  GPIO_InitStruct.Alternate = LL_GPIO_AF_5;
  LL_GPIO_Init(EXP_SPI_NSS_GPIO_Port, &GPIO_InitStruct);

  GPIO_InitStruct.Pin = EXP_SPI_SCK_Pin;
  GPIO_InitStruct.Mode = LL_GPIO_MODE_ALTERNATE;
  GPIO_InitStruct.Speed = LL_GPIO_SPEED_FREQ_VERY_HIGH;
  GPIO_InitStruct.OutputType = LL_GPIO_OUTPUT_PUSHPULL;
  GPIO_InitStruct.Pull = LL_GPIO_PULL_NO;
  GPIO_InitStruct.Alternate = LL_GPIO_AF_5;
  LL_GPIO_Init(EXP_SPI_SCK_GPIO_Port, &GPIO_InitStruct);

  GPIO_InitStruct.Pin = EXP_SPI_MISO_Pin;
  GPIO_InitStruct.Mode = LL_GPIO_MODE_ALTERNATE;
  GPIO_InitStruct.Speed = LL_GPIO_SPEED_FREQ_VERY_HIGH;
  GPIO_InitStruct.OutputType = LL_GPIO_OUTPUT_PUSHPULL;
  GPIO_InitStruct.Pull = LL_GPIO_PULL_NO;
  GPIO_InitStruct.Alternate = LL_GPIO_AF_5;
  LL_GPIO_Init(EXP_SPI_MISO_GPIO_Port, &GPIO_InitStruct);

  GPIO_InitStruct.Pin = EXP_SPI_MOSI_Pin;
  GPIO_InitStruct.Mode = LL_GPIO_MODE_ALTERNATE;
  GPIO_InitStruct.Speed = LL_GPIO_SPEED_FREQ_VERY_HIGH;
  GPIO_InitStruct.OutputType = LL_GPIO_OUTPUT_PUSHPULL;
  GPIO_InitStruct.Pull = LL_GPIO_PULL_NO;
  GPIO_InitStruct.Alternate = LL_GPIO_AF_5;
  LL_GPIO_Init(EXP_SPI_MOSI_GPIO_Port, &GPIO_InitStruct);

  /* SPI1 DMA Init */

  /* SPI1_TX Init */
  LL_DMA_SetChannelSelection(DMA2, LL_DMA_STREAM_3, LL_DMA_CHANNEL_3);

  LL_DMA_SetDataTransferDirection(DMA2, LL_DMA_STREAM_3, LL_DMA_DIRECTION_MEMORY_TO_PERIPH);

  LL_DMA_SetStreamPriorityLevel(DMA2, LL_DMA_STREAM_3, LL_DMA_PRIORITY_HIGH);

  LL_DMA_SetMode(DMA2, LL_DMA_STREAM_3, LL_DMA_MODE_NORMAL);

  LL_DMA_SetPeriphIncMode(DMA2, LL_DMA_STREAM_3, LL_DMA_PERIPH_NOINCREMENT);

  LL_DMA_SetMemoryIncMode(DMA2, LL_DMA_STREAM_3, LL_DMA_MEMORY_INCREMENT);

  LL_DMA_SetPeriphSize(DMA2, LL_DMA_STREAM_3, LL_DMA_PDATAALIGN_BYTE);

  LL_DMA_SetMemorySize(DMA2, LL_DMA_STREAM_3, LL_DMA_MDATAALIGN_BYTE);

  LL_DMA_DisableFifoMode(DMA2, LL_DMA_STREAM_3);

  /* SPI1 parameter configuration*/
  SPI_InitStruct.TransferDirection = LL_SPI_FULL_DUPLEX;
  SPI_InitStruct.Mode = LL_SPI_MODE_SLAVE;
  SPI_InitStruct.DataWidth = LL_SPI_DATAWIDTH_8BIT;
  SPI_InitStruct.ClockPolarity = LL_SPI_POLARITY_HIGH;
  SPI_InitStruct.ClockPhase = LL_SPI_PHASE_1EDGE;
  SPI_InitStruct.NSS = LL_SPI_NSS_HARD_INPUT;
  SPI_InitStruct.BitOrder = LL_SPI_MSB_FIRST;
  SPI_InitStruct.CRCCalculation = LL_SPI_CRCCALCULATION_DISABLE;
  SPI_InitStruct.CRCPoly = 7;
  LL_SPI_Init(SPI1, &SPI_InitStruct);
  LL_SPI_SetStandard(SPI1, LL_SPI_PROTOCOL_MOTOROLA);
  LL_SPI_DisableNSSPulseMgt(SPI1);

}

static void MX_SPI2_Init(void)
{

  LL_SPI_InitTypeDef SPI_InitStruct = {0};

  LL_GPIO_InitTypeDef GPIO_InitStruct = {0};

  /* Peripheral clock enable */
  LL_APB1_GRP1_EnableClock(LL_APB1_GRP1_PERIPH_SPI2);

  LL_AHB1_GRP1_EnableClock(LL_AHB1_GRP1_PERIPH_GPIOB);
  /**SPI2 GPIO Configuration
  PB13   ------> SPI2_SCK
  PB14   ------> SPI2_MISO
  PB15   ------> SPI2_MOSI
  */
  GPIO_InitStruct.Pin = LASER_SCK_Pin;
  GPIO_InitStruct.Mode = LL_GPIO_MODE_ALTERNATE;
  GPIO_InitStruct.Speed = LL_GPIO_SPEED_FREQ_VERY_HIGH;
  GPIO_InitStruct.OutputType = LL_GPIO_OUTPUT_PUSHPULL;
  GPIO_InitStruct.Pull = LL_GPIO_PULL_NO;
  GPIO_InitStruct.Alternate = LL_GPIO_AF_5;
  LL_GPIO_Init(LASER_SCK_GPIO_Port, &GPIO_InitStruct);

  GPIO_InitStruct.Pin = LASER_MISO_Pin;
  GPIO_InitStruct.Mode = LL_GPIO_MODE_ALTERNATE;
  GPIO_InitStruct.Speed = LL_GPIO_SPEED_FREQ_VERY_HIGH;
  GPIO_InitStruct.OutputType = LL_GPIO_OUTPUT_PUSHPULL;
  GPIO_InitStruct.Pull = LL_GPIO_PULL_NO;
  GPIO_InitStruct.Alternate = LL_GPIO_AF_5;
  LL_GPIO_Init(LASER_MISO_GPIO_Port, &GPIO_InitStruct);

  GPIO_InitStruct.Pin = LASER_MOSI_Pin;
  GPIO_InitStruct.Mode = LL_GPIO_MODE_ALTERNATE;
  GPIO_InitStruct.Speed = LL_GPIO_SPEED_FREQ_VERY_HIGH;
  GPIO_InitStruct.OutputType = LL_GPIO_OUTPUT_PUSHPULL;
  GPIO_InitStruct.Pull = LL_GPIO_PULL_NO;
  GPIO_InitStruct.Alternate = LL_GPIO_AF_5;
  LL_GPIO_Init(LASER_MOSI_GPIO_Port, &GPIO_InitStruct);

  /* SPI2 parameter configuration*/
  SPI_InitStruct.TransferDirection = LL_SPI_FULL_DUPLEX;
  SPI_InitStruct.Mode = LL_SPI_MODE_MASTER;
  SPI_InitStruct.DataWidth = LL_SPI_DATAWIDTH_8BIT;
  SPI_InitStruct.ClockPolarity = LL_SPI_POLARITY_LOW;
  SPI_InitStruct.ClockPhase = LL_SPI_PHASE_2EDGE;
  SPI_InitStruct.NSS = LL_SPI_NSS_SOFT;
  SPI_InitStruct.BaudRate = LL_SPI_BAUDRATEPRESCALER_DIV16;
  SPI_InitStruct.BitOrder = LL_SPI_MSB_FIRST;
  SPI_InitStruct.CRCCalculation = LL_SPI_CRCCALCULATION_DISABLE;
  SPI_InitStruct.CRCPoly = 7;
  LL_SPI_Init(SPI2, &SPI_InitStruct);
  LL_SPI_SetStandard(SPI2, LL_SPI_PROTOCOL_MOTOROLA);
  LL_SPI_DisableNSSPulseMgt(SPI2);
  /* USER CODE BEGIN SPI2_Init 2 */
  LL_SPI_Enable(SPI2);
  /* USER CODE END SPI2_Init 2 */

}

static void MX_SPI3_Init(void)
{

  LL_SPI_InitTypeDef SPI_InitStruct = {0};

  LL_GPIO_InitTypeDef GPIO_InitStruct = {0};

  /* Peripheral clock enable */
  LL_APB1_GRP1_EnableClock(LL_APB1_GRP1_PERIPH_SPI3);

  LL_AHB1_GRP1_EnableClock(LL_AHB1_GRP1_PERIPH_GPIOC);
  /**SPI3 GPIO Configuration
  PC10   ------> SPI3_SCK
  PC11   ------> SPI3_MISO
  PC12   ------> SPI3_MOSI
  */
  GPIO_InitStruct.Pin = TEC_SCK_Pin;
  GPIO_InitStruct.Mode = LL_GPIO_MODE_ALTERNATE;
  GPIO_InitStruct.Speed = LL_GPIO_SPEED_FREQ_VERY_HIGH;
  GPIO_InitStruct.OutputType = LL_GPIO_OUTPUT_PUSHPULL;
  GPIO_InitStruct.Pull = LL_GPIO_PULL_NO;
  GPIO_InitStruct.Alternate = LL_GPIO_AF_6;
  LL_GPIO_Init(TEC_SCK_GPIO_Port, &GPIO_InitStruct);

  GPIO_InitStruct.Pin = TEC_MISO_Pin;
  GPIO_InitStruct.Mode = LL_GPIO_MODE_ALTERNATE;
  GPIO_InitStruct.Speed = LL_GPIO_SPEED_FREQ_VERY_HIGH;
  GPIO_InitStruct.OutputType = LL_GPIO_OUTPUT_PUSHPULL;
  GPIO_InitStruct.Pull = LL_GPIO_PULL_NO;
  GPIO_InitStruct.Alternate = LL_GPIO_AF_6;
  LL_GPIO_Init(TEC_MISO_GPIO_Port, &GPIO_InitStruct);

  GPIO_InitStruct.Pin = TEC_MOSI_Pin;
  GPIO_InitStruct.Mode = LL_GPIO_MODE_ALTERNATE;
  GPIO_InitStruct.Speed = LL_GPIO_SPEED_FREQ_VERY_HIGH;
  GPIO_InitStruct.OutputType = LL_GPIO_OUTPUT_PUSHPULL;
  GPIO_InitStruct.Pull = LL_GPIO_PULL_NO;
  GPIO_InitStruct.Alternate = LL_GPIO_AF_6;
  LL_GPIO_Init(TEC_MOSI_GPIO_Port, &GPIO_InitStruct);

  /* SPI3 parameter configuration*/
  SPI_InitStruct.TransferDirection = LL_SPI_FULL_DUPLEX;
  SPI_InitStruct.Mode = LL_SPI_MODE_MASTER;
  SPI_InitStruct.DataWidth = LL_SPI_DATAWIDTH_8BIT;
  SPI_InitStruct.ClockPolarity = LL_SPI_POLARITY_LOW;
  SPI_InitStruct.ClockPhase = LL_SPI_PHASE_1EDGE;
  SPI_InitStruct.NSS = LL_SPI_NSS_SOFT;
  SPI_InitStruct.BaudRate = LL_SPI_BAUDRATEPRESCALER_DIV2;
  SPI_InitStruct.BitOrder = LL_SPI_MSB_FIRST;
  SPI_InitStruct.CRCCalculation = LL_SPI_CRCCALCULATION_DISABLE;
  SPI_InitStruct.CRCPoly = 7;
  LL_SPI_Init(SPI3, &SPI_InitStruct);
  LL_SPI_SetStandard(SPI3, LL_SPI_PROTOCOL_MOTOROLA);
  LL_SPI_EnableNSSPulseMgt(SPI3);
  /* USER CODE BEGIN SPI3_Init 2 */
  LL_SPI_Enable(SPI3);
  /* USER CODE END SPI3_Init 2 */

}

static void MX_SPI4_Init(void)
{

  LL_SPI_InitTypeDef SPI_InitStruct = {0};

  LL_GPIO_InitTypeDef GPIO_InitStruct = {0};

  /* Peripheral clock enable */
  LL_APB2_GRP1_EnableClock(LL_APB2_GRP1_PERIPH_SPI4);

  LL_AHB1_GRP1_EnableClock(LL_AHB1_GRP1_PERIPH_GPIOE);
  /**SPI4 GPIO Configuration
  PE12   ------> SPI4_SCK
  PE13   ------> SPI4_MISO
  PE14   ------> SPI4_MOSI
  */
  GPIO_InitStruct.Pin = PHOTO_SCK_Pin;
  GPIO_InitStruct.Mode = LL_GPIO_MODE_ALTERNATE;
  GPIO_InitStruct.Speed = LL_GPIO_SPEED_FREQ_VERY_HIGH;
  GPIO_InitStruct.OutputType = LL_GPIO_OUTPUT_PUSHPULL;
  GPIO_InitStruct.Pull = LL_GPIO_PULL_NO;
  GPIO_InitStruct.Alternate = LL_GPIO_AF_5;
  LL_GPIO_Init(PHOTO_SCK_GPIO_Port, &GPIO_InitStruct);

  GPIO_InitStruct.Pin = PHOTO_MISO_Pin;
  GPIO_InitStruct.Mode = LL_GPIO_MODE_ALTERNATE;
  GPIO_InitStruct.Speed = LL_GPIO_SPEED_FREQ_VERY_HIGH;
  GPIO_InitStruct.OutputType = LL_GPIO_OUTPUT_PUSHPULL;
  GPIO_InitStruct.Pull = LL_GPIO_PULL_NO;
  GPIO_InitStruct.Alternate = LL_GPIO_AF_5;
  LL_GPIO_Init(PHOTO_MISO_GPIO_Port, &GPIO_InitStruct);

  GPIO_InitStruct.Pin = PHOTO_MOSI_Pin;
  GPIO_InitStruct.Mode = LL_GPIO_MODE_ALTERNATE;
  GPIO_InitStruct.Speed = LL_GPIO_SPEED_FREQ_VERY_HIGH;
  GPIO_InitStruct.OutputType = LL_GPIO_OUTPUT_PUSHPULL;
  GPIO_InitStruct.Pull = LL_GPIO_PULL_NO;
  GPIO_InitStruct.Alternate = LL_GPIO_AF_5;
  LL_GPIO_Init(PHOTO_MOSI_GPIO_Port, &GPIO_InitStruct);

  /* SPI4 DMA Init */

  /* SPI4_RX Init */
  LL_DMA_SetChannelSelection(DMA2, LL_DMA_STREAM_0, LL_DMA_CHANNEL_4);

  LL_DMA_SetDataTransferDirection(DMA2, LL_DMA_STREAM_0, LL_DMA_DIRECTION_PERIPH_TO_MEMORY);

  LL_DMA_SetStreamPriorityLevel(DMA2, LL_DMA_STREAM_0, LL_DMA_PRIORITY_VERYHIGH);

  LL_DMA_SetMode(DMA2, LL_DMA_STREAM_0, LL_DMA_MODE_CIRCULAR);

  LL_DMA_SetPeriphIncMode(DMA2, LL_DMA_STREAM_0, LL_DMA_PERIPH_NOINCREMENT);

  LL_DMA_SetMemoryIncMode(DMA2, LL_DMA_STREAM_0, LL_DMA_MEMORY_INCREMENT);

  LL_DMA_SetPeriphSize(DMA2, LL_DMA_STREAM_0, LL_DMA_PDATAALIGN_HALFWORD);

  LL_DMA_SetMemorySize(DMA2, LL_DMA_STREAM_0, LL_DMA_MDATAALIGN_HALFWORD);

  LL_DMA_DisableFifoMode(DMA2, LL_DMA_STREAM_0);

  /* SPI4 parameter configuration*/
  SPI_InitStruct.TransferDirection = LL_SPI_FULL_DUPLEX;
  SPI_InitStruct.Mode = LL_SPI_MODE_MASTER;
  SPI_InitStruct.DataWidth = LL_SPI_DATAWIDTH_16BIT;
  SPI_InitStruct.ClockPolarity = LL_SPI_POLARITY_LOW;
  SPI_InitStruct.ClockPhase = LL_SPI_PHASE_1EDGE;
  SPI_InitStruct.NSS = LL_SPI_NSS_SOFT;
  SPI_InitStruct.BaudRate = LL_SPI_BAUDRATEPRESCALER_DIV4;
  SPI_InitStruct.BitOrder = LL_SPI_MSB_FIRST;
  SPI_InitStruct.CRCCalculation = LL_SPI_CRCCALCULATION_DISABLE;
  SPI_InitStruct.CRCPoly = 7;
  LL_SPI_Init(SPI4, &SPI_InitStruct);
  LL_SPI_SetStandard(SPI4, LL_SPI_PROTOCOL_MOTOROLA);
  LL_SPI_EnableNSSPulseMgt(SPI4);
  /* USER CODE BEGIN SPI4_Init 2 */
  LL_SPI_Enable(SPI4);
  /* USER CODE END SPI4_Init 2 */

}

static void MX_SPI6_Init(void)
{

  LL_SPI_InitTypeDef SPI_InitStruct = {0};

  LL_GPIO_InitTypeDef GPIO_InitStruct = {0};

  /* Peripheral clock enable */
  LL_APB2_GRP1_EnableClock(LL_APB2_GRP1_PERIPH_SPI6);

  LL_AHB1_GRP1_EnableClock(LL_AHB1_GRP1_PERIPH_GPIOB);
  /**SPI6 GPIO Configuration
  PB3   ------> SPI6_SCK
  PB4   ------> SPI6_MISO
  PB5   ------> SPI6_MOSI
  */
  GPIO_InitStruct.Pin = FRAM_SCK_Pin;
  GPIO_InitStruct.Mode = LL_GPIO_MODE_ALTERNATE;
  GPIO_InitStruct.Speed = LL_GPIO_SPEED_FREQ_VERY_HIGH;
  GPIO_InitStruct.OutputType = LL_GPIO_OUTPUT_PUSHPULL;
  GPIO_InitStruct.Pull = LL_GPIO_PULL_NO;
  GPIO_InitStruct.Alternate = LL_GPIO_AF_8;
  LL_GPIO_Init(FRAM_SCK_GPIO_Port, &GPIO_InitStruct);

  GPIO_InitStruct.Pin = FRAM_MISO_Pin;
  GPIO_InitStruct.Mode = LL_GPIO_MODE_ALTERNATE;
  GPIO_InitStruct.Speed = LL_GPIO_SPEED_FREQ_VERY_HIGH;
  GPIO_InitStruct.OutputType = LL_GPIO_OUTPUT_PUSHPULL;
  GPIO_InitStruct.Pull = LL_GPIO_PULL_NO;
  GPIO_InitStruct.Alternate = LL_GPIO_AF_8;
  LL_GPIO_Init(FRAM_MISO_GPIO_Port, &GPIO_InitStruct);

  GPIO_InitStruct.Pin = FRAM_MOSI_Pin;
  GPIO_InitStruct.Mode = LL_GPIO_MODE_ALTERNATE;
  GPIO_InitStruct.Speed = LL_GPIO_SPEED_FREQ_VERY_HIGH;
  GPIO_InitStruct.OutputType = LL_GPIO_OUTPUT_PUSHPULL;
  GPIO_InitStruct.Pull = LL_GPIO_PULL_NO;
  GPIO_InitStruct.Alternate = LL_GPIO_AF_8;
  LL_GPIO_Init(FRAM_MOSI_GPIO_Port, &GPIO_InitStruct);

  /* SPI6 DMA Init */

  /* SPI6_TX Init */
  LL_DMA_SetChannelSelection(DMA2, LL_DMA_STREAM_5, LL_DMA_CHANNEL_1);

  LL_DMA_SetDataTransferDirection(DMA2, LL_DMA_STREAM_5, LL_DMA_DIRECTION_MEMORY_TO_PERIPH);

  LL_DMA_SetStreamPriorityLevel(DMA2, LL_DMA_STREAM_5, LL_DMA_PRIORITY_VERYHIGH);

  LL_DMA_SetMode(DMA2, LL_DMA_STREAM_5, LL_DMA_MODE_NORMAL);

  LL_DMA_SetPeriphIncMode(DMA2, LL_DMA_STREAM_5, LL_DMA_PERIPH_NOINCREMENT);

  LL_DMA_SetMemoryIncMode(DMA2, LL_DMA_STREAM_5, LL_DMA_MEMORY_INCREMENT);

  LL_DMA_SetPeriphSize(DMA2, LL_DMA_STREAM_5, LL_DMA_PDATAALIGN_BYTE);

  LL_DMA_SetMemorySize(DMA2, LL_DMA_STREAM_5, LL_DMA_MDATAALIGN_BYTE);

  LL_DMA_DisableFifoMode(DMA2, LL_DMA_STREAM_5);

  /* SPI6_RX Init */
  LL_DMA_SetChannelSelection(DMA2, LL_DMA_STREAM_6, LL_DMA_CHANNEL_1);

  LL_DMA_SetDataTransferDirection(DMA2, LL_DMA_STREAM_6, LL_DMA_DIRECTION_PERIPH_TO_MEMORY);

  LL_DMA_SetStreamPriorityLevel(DMA2, LL_DMA_STREAM_6, LL_DMA_PRIORITY_VERYHIGH);

  LL_DMA_SetMode(DMA2, LL_DMA_STREAM_6, LL_DMA_MODE_NORMAL);

  LL_DMA_SetPeriphIncMode(DMA2, LL_DMA_STREAM_6, LL_DMA_PERIPH_NOINCREMENT);

  LL_DMA_SetMemoryIncMode(DMA2, LL_DMA_STREAM_6, LL_DMA_MEMORY_INCREMENT);

  LL_DMA_SetPeriphSize(DMA2, LL_DMA_STREAM_6, LL_DMA_PDATAALIGN_BYTE);

  LL_DMA_SetMemorySize(DMA2, LL_DMA_STREAM_6, LL_DMA_MDATAALIGN_BYTE);

  LL_DMA_DisableFifoMode(DMA2, LL_DMA_STREAM_6);

  /* SPI6 parameter configuration*/
  SPI_InitStruct.TransferDirection = LL_SPI_FULL_DUPLEX;
  SPI_InitStruct.Mode = LL_SPI_MODE_MASTER;
  SPI_InitStruct.DataWidth = LL_SPI_DATAWIDTH_8BIT;
  SPI_InitStruct.ClockPolarity = LL_SPI_POLARITY_LOW;
  SPI_InitStruct.ClockPhase = LL_SPI_PHASE_1EDGE;
  SPI_InitStruct.NSS = LL_SPI_NSS_SOFT;
  SPI_InitStruct.BaudRate = LL_SPI_BAUDRATEPRESCALER_DIV2;
  SPI_InitStruct.BitOrder = LL_SPI_MSB_FIRST;
  SPI_InitStruct.CRCCalculation = LL_SPI_CRCCALCULATION_DISABLE;
  SPI_InitStruct.CRCPoly = 7;
  LL_SPI_Init(SPI6, &SPI_InitStruct);
  LL_SPI_SetStandard(SPI6, LL_SPI_PROTOCOL_MOTOROLA);
  LL_SPI_EnableNSSPulseMgt(SPI6);
  /* USER CODE BEGIN SPI6_Init 2 */
  LL_SPI_Enable(SPI6);
  /* USER CODE END SPI6_Init 2 */

}

static void MX_TIM1_Init(void)
{

  LL_TIM_InitTypeDef TIM_InitStruct = {0};

  /* Peripheral clock enable */
  LL_APB2_GRP1_EnableClock(LL_APB2_GRP1_PERIPH_TIM1);

  /* TIM1 interrupt Init */
  NVIC_SetPriority(TIM1_UP_TIM10_IRQn, NVIC_EncodePriority(NVIC_GetPriorityGrouping(),0, 0));
  NVIC_EnableIRQ(TIM1_UP_TIM10_IRQn);

  TIM_InitStruct.Prescaler = 0;
  TIM_InitStruct.CounterMode = LL_TIM_COUNTERMODE_UP;
  TIM_InitStruct.Autoreload = 65535;
  TIM_InitStruct.ClockDivision = LL_TIM_CLOCKDIVISION_DIV1;
  TIM_InitStruct.RepetitionCounter = 0;
  LL_TIM_Init(TIM1, &TIM_InitStruct);
  LL_TIM_DisableARRPreload(TIM1);
  LL_TIM_SetClockSource(TIM1, LL_TIM_CLOCKSOURCE_INTERNAL);
  LL_TIM_SetTriggerOutput(TIM1, LL_TIM_TRGO_RESET);
  LL_TIM_SetTriggerOutput2(TIM1, LL_TIM_TRGO2_RESET);
  LL_TIM_DisableMasterSlaveMode(TIM1);

}

static void MX_TIM2_Init(void)
{

  LL_TIM_InitTypeDef TIM_InitStruct = {0};

  /* Peripheral clock enable */
  LL_APB1_GRP1_EnableClock(LL_APB1_GRP1_PERIPH_TIM2);

  /* TIM2 interrupt Init */
  NVIC_SetPriority(TIM2_IRQn, NVIC_EncodePriority(NVIC_GetPriorityGrouping(),2, 0));
  NVIC_EnableIRQ(TIM2_IRQn);

  TIM_InitStruct.Prescaler = 0;
  TIM_InitStruct.CounterMode = LL_TIM_COUNTERMODE_UP;
  TIM_InitStruct.Autoreload = 4294967295;
  TIM_InitStruct.ClockDivision = LL_TIM_CLOCKDIVISION_DIV1;
  LL_TIM_Init(TIM2, &TIM_InitStruct);
  LL_TIM_EnableARRPreload(TIM2);
  LL_TIM_SetClockSource(TIM2, LL_TIM_CLOCKSOURCE_INTERNAL);
  LL_TIM_SetTriggerOutput(TIM2, LL_TIM_TRGO_RESET);
  LL_TIM_DisableMasterSlaveMode(TIM2);

}

static void MX_TIM4_Init(void)
{

  LL_TIM_InitTypeDef TIM_InitStruct = {0};
  LL_TIM_OC_InitTypeDef TIM_OC_InitStruct = {0};

  LL_GPIO_InitTypeDef GPIO_InitStruct = {0};

  /* Peripheral clock enable */
  LL_APB1_GRP1_EnableClock(LL_APB1_GRP1_PERIPH_TIM4);

  TIM_InitStruct.Prescaler = 10;
  TIM_InitStruct.CounterMode = LL_TIM_COUNTERMODE_UP;
  TIM_InitStruct.Autoreload = 50000;
  TIM_InitStruct.ClockDivision = LL_TIM_CLOCKDIVISION_DIV4;
  LL_TIM_Init(TIM4, &TIM_InitStruct);
  LL_TIM_DisableARRPreload(TIM4);
  LL_TIM_SetClockSource(TIM4, LL_TIM_CLOCKSOURCE_INTERNAL);
  LL_TIM_OC_EnablePreload(TIM4, LL_TIM_CHANNEL_CH1);
  TIM_OC_InitStruct.OCMode = LL_TIM_OCMODE_PWM1;
  TIM_OC_InitStruct.OCState = LL_TIM_OCSTATE_DISABLE;
  TIM_OC_InitStruct.OCNState = LL_TIM_OCSTATE_DISABLE;
  TIM_OC_InitStruct.CompareValue = 0;
  TIM_OC_InitStruct.OCPolarity = LL_TIM_OCPOLARITY_HIGH;
  LL_TIM_OC_Init(TIM4, LL_TIM_CHANNEL_CH1, &TIM_OC_InitStruct);
  LL_TIM_OC_DisableFast(TIM4, LL_TIM_CHANNEL_CH1);
  LL_TIM_OC_EnablePreload(TIM4, LL_TIM_CHANNEL_CH2);
  LL_TIM_OC_Init(TIM4, LL_TIM_CHANNEL_CH2, &TIM_OC_InitStruct);
  LL_TIM_OC_DisableFast(TIM4, LL_TIM_CHANNEL_CH2);
  LL_TIM_OC_EnablePreload(TIM4, LL_TIM_CHANNEL_CH3);
  LL_TIM_OC_Init(TIM4, LL_TIM_CHANNEL_CH3, &TIM_OC_InitStruct);
  LL_TIM_OC_DisableFast(TIM4, LL_TIM_CHANNEL_CH3);
  LL_TIM_OC_EnablePreload(TIM4, LL_TIM_CHANNEL_CH4);
  LL_TIM_OC_Init(TIM4, LL_TIM_CHANNEL_CH4, &TIM_OC_InitStruct);
  LL_TIM_OC_DisableFast(TIM4, LL_TIM_CHANNEL_CH4);
  LL_TIM_SetTriggerOutput(TIM4, LL_TIM_TRGO_RESET);
  LL_TIM_DisableMasterSlaveMode(TIM4);
  LL_AHB1_GRP1_EnableClock(LL_AHB1_GRP1_PERIPH_GPIOD);
  /**TIM4 GPIO Configuration
  PD12   ------> TIM4_CH1
  PD13   ------> TIM4_CH2
  PD14   ------> TIM4_CH3
  PD15   ------> TIM4_CH4
  */
  GPIO_InitStruct.Pin = LL_GPIO_PIN_12;
  GPIO_InitStruct.Mode = LL_GPIO_MODE_ALTERNATE;
  GPIO_InitStruct.Speed = LL_GPIO_SPEED_FREQ_LOW;
  GPIO_InitStruct.OutputType = LL_GPIO_OUTPUT_PUSHPULL;
  GPIO_InitStruct.Pull = LL_GPIO_PULL_NO;
  GPIO_InitStruct.Alternate = LL_GPIO_AF_2;
  LL_GPIO_Init(GPIOD, &GPIO_InitStruct);

  GPIO_InitStruct.Pin = LL_GPIO_PIN_13;
  GPIO_InitStruct.Mode = LL_GPIO_MODE_ALTERNATE;
  GPIO_InitStruct.Speed = LL_GPIO_SPEED_FREQ_LOW;
  GPIO_InitStruct.OutputType = LL_GPIO_OUTPUT_PUSHPULL;
  GPIO_InitStruct.Pull = LL_GPIO_PULL_NO;
  GPIO_InitStruct.Alternate = LL_GPIO_AF_2;
  LL_GPIO_Init(GPIOD, &GPIO_InitStruct);

  GPIO_InitStruct.Pin = LL_GPIO_PIN_14;
  GPIO_InitStruct.Mode = LL_GPIO_MODE_ALTERNATE;
  GPIO_InitStruct.Speed = LL_GPIO_SPEED_FREQ_LOW;
  GPIO_InitStruct.OutputType = LL_GPIO_OUTPUT_PUSHPULL;
  GPIO_InitStruct.Pull = LL_GPIO_PULL_NO;
  GPIO_InitStruct.Alternate = LL_GPIO_AF_2;
  LL_GPIO_Init(GPIOD, &GPIO_InitStruct);

  GPIO_InitStruct.Pin = LL_GPIO_PIN_15;
  GPIO_InitStruct.Mode = LL_GPIO_MODE_ALTERNATE;
  GPIO_InitStruct.Speed = LL_GPIO_SPEED_FREQ_LOW;
  GPIO_InitStruct.OutputType = LL_GPIO_OUTPUT_PUSHPULL;
  GPIO_InitStruct.Pull = LL_GPIO_PULL_NO;
  GPIO_InitStruct.Alternate = LL_GPIO_AF_2;
  LL_GPIO_Init(GPIOD, &GPIO_InitStruct);

}

static void MX_UART7_Init(void)
{

  LL_USART_InitTypeDef USART_InitStruct = {0};

  LL_GPIO_InitTypeDef GPIO_InitStruct = {0};
  RCC_PeriphCLKInitTypeDef PeriphClkInitStruct = {0};

  /** Initializes the peripherals clock
  */
  PeriphClkInitStruct.PeriphClockSelection = RCC_PERIPHCLK_UART7;
  PeriphClkInitStruct.Uart7ClockSelection = RCC_UART7CLKSOURCE_PCLK1;
  if (HAL_RCCEx_PeriphCLKConfig(&PeriphClkInitStruct) != HAL_OK)
  {
    Error_Handler();
  }

  /* Peripheral clock enable */
  LL_APB1_GRP1_EnableClock(LL_APB1_GRP1_PERIPH_UART7);

  LL_AHB1_GRP1_EnableClock(LL_AHB1_GRP1_PERIPH_GPIOE);
  /**UART7 GPIO Configuration
  PE7   ------> UART7_RX
  PE8   ------> UART7_TX
  */
  GPIO_InitStruct.Pin = EXP_UART_RX_Pin;
  GPIO_InitStruct.Mode = LL_GPIO_MODE_ALTERNATE;
  GPIO_InitStruct.Speed = LL_GPIO_SPEED_FREQ_VERY_HIGH;
  GPIO_InitStruct.OutputType = LL_GPIO_OUTPUT_PUSHPULL;
  GPIO_InitStruct.Pull = LL_GPIO_PULL_UP;
  GPIO_InitStruct.Alternate = LL_GPIO_AF_8;
  LL_GPIO_Init(EXP_UART_RX_GPIO_Port, &GPIO_InitStruct);

  GPIO_InitStruct.Pin = EXP_UART_TX_Pin;
  GPIO_InitStruct.Mode = LL_GPIO_MODE_ALTERNATE;
  GPIO_InitStruct.Speed = LL_GPIO_SPEED_FREQ_VERY_HIGH;
  GPIO_InitStruct.OutputType = LL_GPIO_OUTPUT_PUSHPULL;
  GPIO_InitStruct.Pull = LL_GPIO_PULL_NO;
  GPIO_InitStruct.Alternate = LL_GPIO_AF_8;
  LL_GPIO_Init(EXP_UART_TX_GPIO_Port, &GPIO_InitStruct);

  /* UART7 interrupt Init */
  NVIC_SetPriority(UART7_IRQn, NVIC_EncodePriority(NVIC_GetPriorityGrouping(),11, 0));
  NVIC_EnableIRQ(UART7_IRQn);

  USART_InitStruct.BaudRate = 115200;
  USART_InitStruct.DataWidth = LL_USART_DATAWIDTH_8B;
  USART_InitStruct.StopBits = LL_USART_STOPBITS_1;
  USART_InitStruct.Parity = LL_USART_PARITY_NONE;
  USART_InitStruct.TransferDirection = LL_USART_DIRECTION_TX_RX;
  USART_InitStruct.HardwareFlowControl = LL_USART_HWCONTROL_NONE;
  USART_InitStruct.OverSampling = LL_USART_OVERSAMPLING_16;
  LL_USART_Init(UART7, &USART_InitStruct);
  LL_USART_ConfigAsyncMode(UART7);
  LL_USART_Enable(UART7);

}

static void MX_USART1_UART_Init(void)
{

  LL_USART_InitTypeDef USART_InitStruct = {0};

  LL_GPIO_InitTypeDef GPIO_InitStruct = {0};
  RCC_PeriphCLKInitTypeDef PeriphClkInitStruct = {0};

  /** Initializes the peripherals clock
  */
  PeriphClkInitStruct.PeriphClockSelection = RCC_PERIPHCLK_USART1;
  PeriphClkInitStruct.Usart1ClockSelection = RCC_USART1CLKSOURCE_PCLK2;
  if (HAL_RCCEx_PeriphCLKConfig(&PeriphClkInitStruct) != HAL_OK)
  {
    Error_Handler();
  }

  /* Peripheral clock enable */
  LL_APB2_GRP1_EnableClock(LL_APB2_GRP1_PERIPH_USART1);

  LL_AHB1_GRP1_EnableClock(LL_AHB1_GRP1_PERIPH_GPIOA);
  /**USART1 GPIO Configuration
  PA9   ------> USART1_TX
  PA10   ------> USART1_RX
  PA12   ------> USART1_DE
  */
  GPIO_InitStruct.Pin = RS485_TX_Pin;
  GPIO_InitStruct.Mode = LL_GPIO_MODE_ALTERNATE;
  GPIO_InitStruct.Speed = LL_GPIO_SPEED_FREQ_VERY_HIGH;
  GPIO_InitStruct.OutputType = LL_GPIO_OUTPUT_PUSHPULL;
  GPIO_InitStruct.Pull = LL_GPIO_PULL_NO;
  GPIO_InitStruct.Alternate = LL_GPIO_AF_7;
  LL_GPIO_Init(RS485_TX_GPIO_Port, &GPIO_InitStruct);

  GPIO_InitStruct.Pin = RS485_RX_Pin;
  GPIO_InitStruct.Mode = LL_GPIO_MODE_ALTERNATE;
  GPIO_InitStruct.Speed = LL_GPIO_SPEED_FREQ_VERY_HIGH;
  GPIO_InitStruct.OutputType = LL_GPIO_OUTPUT_PUSHPULL;
  GPIO_InitStruct.Pull = LL_GPIO_PULL_NO;
  GPIO_InitStruct.Alternate = LL_GPIO_AF_7;
  LL_GPIO_Init(RS485_RX_GPIO_Port, &GPIO_InitStruct);

  GPIO_InitStruct.Pin = RS485_DE_Pin;
  GPIO_InitStruct.Mode = LL_GPIO_MODE_ALTERNATE;
  GPIO_InitStruct.Speed = LL_GPIO_SPEED_FREQ_VERY_HIGH;
  GPIO_InitStruct.OutputType = LL_GPIO_OUTPUT_PUSHPULL;
  GPIO_InitStruct.Pull = LL_GPIO_PULL_NO;
  GPIO_InitStruct.Alternate = LL_GPIO_AF_7;
  LL_GPIO_Init(RS485_DE_GPIO_Port, &GPIO_InitStruct);

  USART_InitStruct.BaudRate = 115200;
  USART_InitStruct.DataWidth = LL_USART_DATAWIDTH_8B;
  USART_InitStruct.StopBits = LL_USART_STOPBITS_1;
  USART_InitStruct.Parity = LL_USART_PARITY_NONE;
  USART_InitStruct.TransferDirection = LL_USART_DIRECTION_TX_RX;
  USART_InitStruct.HardwareFlowControl = LL_USART_HWCONTROL_NONE;
  USART_InitStruct.OverSampling = LL_USART_OVERSAMPLING_16;
  LL_USART_Init(USART1, &USART_InitStruct);
  LL_USART_EnableDEMode(USART1);
  LL_USART_SetDESignalPolarity(USART1, LL_USART_DE_POLARITY_HIGH);
  LL_USART_SetDEAssertionTime(USART1, 0);
  LL_USART_SetDEDeassertionTime(USART1, 0);
  LL_USART_ConfigAsyncMode(USART1);
  LL_USART_Enable(USART1);

}

static void MX_DMA_Init(void)
{

  /* Init with LL driver */
  /* DMA controller clock enable */
  LL_AHB1_GRP1_EnableClock(LL_AHB1_GRP1_PERIPH_DMA2);

  /* DMA interrupt init */
  /* DMA2_Stream0_IRQn interrupt configuration */
  NVIC_SetPriority(DMA2_Stream0_IRQn, NVIC_EncodePriority(NVIC_GetPriorityGrouping(),1, 0));
  NVIC_EnableIRQ(DMA2_Stream0_IRQn);
  /* DMA2_Stream2_IRQn interrupt configuration */
  NVIC_SetPriority(DMA2_Stream2_IRQn, NVIC_EncodePriority(NVIC_GetPriorityGrouping(),10, 0));
  NVIC_EnableIRQ(DMA2_Stream2_IRQn);
  /* DMA2_Stream3_IRQn interrupt configuration */
  NVIC_SetPriority(DMA2_Stream3_IRQn, NVIC_EncodePriority(NVIC_GetPriorityGrouping(),1, 0));
  NVIC_EnableIRQ(DMA2_Stream3_IRQn);
  /* DMA2_Stream4_IRQn interrupt configuration */
  NVIC_SetPriority(DMA2_Stream4_IRQn, NVIC_EncodePriority(NVIC_GetPriorityGrouping(),10, 0));
  NVIC_EnableIRQ(DMA2_Stream4_IRQn);
  /* DMA2_Stream5_IRQn interrupt configuration */
  NVIC_SetPriority(DMA2_Stream5_IRQn, NVIC_EncodePriority(NVIC_GetPriorityGrouping(),9, 0));
  NVIC_EnableIRQ(DMA2_Stream5_IRQn);
  /* DMA2_Stream6_IRQn interrupt configuration */
  NVIC_SetPriority(DMA2_Stream6_IRQn, NVIC_EncodePriority(NVIC_GetPriorityGrouping(),9, 0));
  NVIC_EnableIRQ(DMA2_Stream6_IRQn);

}

static void MX_GPIO_Init(void)
{
  LL_GPIO_InitTypeDef GPIO_InitStruct = {0};

  /* GPIO Ports Clock Enable */
  LL_AHB1_GRP1_EnableClock(LL_AHB1_GRP1_PERIPH_GPIOE);
  LL_AHB1_GRP1_EnableClock(LL_AHB1_GRP1_PERIPH_GPIOC);
  LL_AHB1_GRP1_EnableClock(LL_AHB1_GRP1_PERIPH_GPIOH);
  LL_AHB1_GRP1_EnableClock(LL_AHB1_GRP1_PERIPH_GPIOA);
  LL_AHB1_GRP1_EnableClock(LL_AHB1_GRP1_PERIPH_GPIOB);
  LL_AHB1_GRP1_EnableClock(LL_AHB1_GRP1_PERIPH_GPIOD);

  /**/
  LL_GPIO_ResetOutputPin(TEC_4_SWEN_GPIO_Port, TEC_4_SWEN_Pin);

  /**/
  LL_GPIO_ResetOutputPin(TEC_3_SWEN_GPIO_Port, TEC_3_SWEN_Pin);

  /**/
  LL_GPIO_ResetOutputPin(TEC_2_SWEN_GPIO_Port, TEC_2_SWEN_Pin);

  /**/
  LL_GPIO_ResetOutputPin(TEC_1_SWEN_GPIO_Port, TEC_1_SWEN_Pin);

  /**/
  LL_GPIO_ResetOutputPin(TEC_1_EN_GPIO_Port, TEC_1_EN_Pin);

  /**/
  LL_GPIO_ResetOutputPin(TEC_2_EN_GPIO_Port, TEC_2_EN_Pin);

  /**/
  LL_GPIO_ResetOutputPin(TEC_3_EN_GPIO_Port, TEC_3_EN_Pin);

  /**/
  LL_GPIO_ResetOutputPin(TEC_4_EN_GPIO_Port, TEC_4_EN_Pin);

  /**/
  LL_GPIO_ResetOutputPin(MIN_HandShake_GPIO_Port, MIN_HandShake_Pin);

  /**/
  LL_GPIO_ResetOutputPin(LED_G_GPIO_Port, LED_G_Pin);

  /**/
  LL_GPIO_ResetOutputPin(LED_B_GPIO_Port, LED_B_Pin);

  /**/
  LL_GPIO_ResetOutputPin(ADG_MOSI_GPIO_Port, ADG_MOSI_Pin);

  /**/
  LL_GPIO_ResetOutputPin(ADG_SCK_GPIO_Port, ADG_SCK_Pin);

  /**/
  LL_GPIO_ResetOutputPin(EF_5_EN_GPIO_Port, EF_5_EN_Pin);

  /**/
  LL_GPIO_ResetOutputPin(SENSOR1_EN_GPIO_Port, SENSOR1_EN_Pin);

  /**/
  LL_GPIO_ResetOutputPin(SENSOR2_EN_GPIO_Port, SENSOR2_EN_Pin);

  /**/
  LL_GPIO_SetOutputPin(LASER_DAC_CS_GPIO_Port, LASER_DAC_CS_Pin);

  /**/
  LL_GPIO_SetOutputPin(LASER_INT_SW_CS_GPIO_Port, LASER_INT_SW_CS_Pin);

  /**/
  LL_GPIO_SetOutputPin(PHOTO_ADC_CS_GPIO_Port, PHOTO_ADC_CS_Pin);

  /**/
  LL_GPIO_SetOutputPin(LASER_EXT_SW_CS_GPIO_Port, LASER_EXT_SW_CS_Pin);

  /**/
  LL_GPIO_SetOutputPin(Log_OverFlow_GPIO_Port, Log_OverFlow_Pin);

  /**/
  LL_GPIO_SetOutputPin(LASER_DAC_LATCH_GPIO_Port, LASER_DAC_LATCH_Pin);

  /**/
  LL_GPIO_SetOutputPin(PHOTO_SW_CS_GPIO_Port, PHOTO_SW_CS_Pin);

  /**/
  LL_GPIO_SetOutputPin(WD_DONE_GPIO_Port, WD_DONE_Pin);

  /**/
  LL_GPIO_SetOutputPin(IRQ_0_GPIO_Port, IRQ_0_Pin);

  /**/
  LL_GPIO_SetOutputPin(PHOTO_ADC_CONV_GPIO_Port, PHOTO_ADC_CONV_Pin);

  /**/
  LL_GPIO_SetOutputPin(ADG_CS_GPIO_Port, ADG_CS_Pin);

  /**/
  LL_GPIO_SetOutputPin(FRAM_CS_GPIO_Port, FRAM_CS_Pin);

  /**/
  LL_GPIO_SetOutputPin(TEC_4_CS_GPIO_Port, TEC_4_CS_Pin);

  /**/
  LL_GPIO_SetOutputPin(TEC_3_CS_GPIO_Port, TEC_3_CS_Pin);

  /**/
  LL_GPIO_SetOutputPin(TEC_2_CS_GPIO_Port, TEC_2_CS_Pin);

  /**/
  LL_GPIO_SetOutputPin(TEC_1_CS_GPIO_Port, TEC_1_CS_Pin);

  /**/
  GPIO_InitStruct.Pin = TEC_4_SWEN_Pin;
  GPIO_InitStruct.Mode = LL_GPIO_MODE_OUTPUT;
  GPIO_InitStruct.Speed = LL_GPIO_SPEED_FREQ_LOW;
  GPIO_InitStruct.OutputType = LL_GPIO_OUTPUT_PUSHPULL;
  GPIO_InitStruct.Pull = LL_GPIO_PULL_NO;
  LL_GPIO_Init(TEC_4_SWEN_GPIO_Port, &GPIO_InitStruct);

  /**/
  GPIO_InitStruct.Pin = TEC_3_SWEN_Pin;
  GPIO_InitStruct.Mode = LL_GPIO_MODE_OUTPUT;
  GPIO_InitStruct.Speed = LL_GPIO_SPEED_FREQ_LOW;
  GPIO_InitStruct.OutputType = LL_GPIO_OUTPUT_PUSHPULL;
  GPIO_InitStruct.Pull = LL_GPIO_PULL_NO;
  LL_GPIO_Init(TEC_3_SWEN_GPIO_Port, &GPIO_InitStruct);

  /**/
  GPIO_InitStruct.Pin = TEC_2_SWEN_Pin;
  GPIO_InitStruct.Mode = LL_GPIO_MODE_OUTPUT;
  GPIO_InitStruct.Speed = LL_GPIO_SPEED_FREQ_LOW;
  GPIO_InitStruct.OutputType = LL_GPIO_OUTPUT_PUSHPULL;
  GPIO_InitStruct.Pull = LL_GPIO_PULL_NO;
  LL_GPIO_Init(TEC_2_SWEN_GPIO_Port, &GPIO_InitStruct);

  /**/
  GPIO_InitStruct.Pin = TEC_1_SWEN_Pin;
  GPIO_InitStruct.Mode = LL_GPIO_MODE_OUTPUT;
  GPIO_InitStruct.Speed = LL_GPIO_SPEED_FREQ_LOW;
  GPIO_InitStruct.OutputType = LL_GPIO_OUTPUT_PUSHPULL;
  GPIO_InitStruct.Pull = LL_GPIO_PULL_NO;
  LL_GPIO_Init(TEC_1_SWEN_GPIO_Port, &GPIO_InitStruct);

  /**/
  GPIO_InitStruct.Pin = TEC_1_EN_Pin;
  GPIO_InitStruct.Mode = LL_GPIO_MODE_OUTPUT;
  GPIO_InitStruct.Speed = LL_GPIO_SPEED_FREQ_LOW;
  GPIO_InitStruct.OutputType = LL_GPIO_OUTPUT_PUSHPULL;
  GPIO_InitStruct.Pull = LL_GPIO_PULL_NO;
  LL_GPIO_Init(TEC_1_EN_GPIO_Port, &GPIO_InitStruct);

  /**/
  GPIO_InitStruct.Pin = TEC_2_EN_Pin;
  GPIO_InitStruct.Mode = LL_GPIO_MODE_OUTPUT;
  GPIO_InitStruct.Speed = LL_GPIO_SPEED_FREQ_LOW;
  GPIO_InitStruct.OutputType = LL_GPIO_OUTPUT_PUSHPULL;
  GPIO_InitStruct.Pull = LL_GPIO_PULL_NO;
  LL_GPIO_Init(TEC_2_EN_GPIO_Port, &GPIO_InitStruct);

  /**/
  GPIO_InitStruct.Pin = TEC_3_EN_Pin;
  GPIO_InitStruct.Mode = LL_GPIO_MODE_OUTPUT;
  GPIO_InitStruct.Speed = LL_GPIO_SPEED_FREQ_LOW;
  GPIO_InitStruct.OutputType = LL_GPIO_OUTPUT_PUSHPULL;
  GPIO_InitStruct.Pull = LL_GPIO_PULL_NO;
  LL_GPIO_Init(TEC_3_EN_GPIO_Port, &GPIO_InitStruct);

  /**/
  GPIO_InitStruct.Pin = TEC_4_EN_Pin;
  GPIO_InitStruct.Mode = LL_GPIO_MODE_OUTPUT;
  GPIO_InitStruct.Speed = LL_GPIO_SPEED_FREQ_LOW;
  GPIO_InitStruct.OutputType = LL_GPIO_OUTPUT_PUSHPULL;
  GPIO_InitStruct.Pull = LL_GPIO_PULL_NO;
  LL_GPIO_Init(TEC_4_EN_GPIO_Port, &GPIO_InitStruct);

  /**/
  GPIO_InitStruct.Pin = ADC_TEC_OUT_Pin;
  GPIO_InitStruct.Mode = LL_GPIO_MODE_ANALOG;
  GPIO_InitStruct.Pull = LL_GPIO_PULL_NO;
  LL_GPIO_Init(ADC_TEC_OUT_GPIO_Port, &GPIO_InitStruct);

  /**/
  GPIO_InitStruct.Pin = LASER_DAC_CS_Pin;
  GPIO_InitStruct.Mode = LL_GPIO_MODE_OUTPUT;
  GPIO_InitStruct.Speed = LL_GPIO_SPEED_FREQ_LOW;
  GPIO_InitStruct.OutputType = LL_GPIO_OUTPUT_PUSHPULL;
  GPIO_InitStruct.Pull = LL_GPIO_PULL_NO;
  LL_GPIO_Init(LASER_DAC_CS_GPIO_Port, &GPIO_InitStruct);

  /**/
  GPIO_InitStruct.Pin = LASER_INT_SW_CS_Pin;
  GPIO_InitStruct.Mode = LL_GPIO_MODE_OUTPUT;
  GPIO_InitStruct.Speed = LL_GPIO_SPEED_FREQ_LOW;
  GPIO_InitStruct.OutputType = LL_GPIO_OUTPUT_PUSHPULL;
  GPIO_InitStruct.Pull = LL_GPIO_PULL_NO;
  LL_GPIO_Init(LASER_INT_SW_CS_GPIO_Port, &GPIO_InitStruct);

  /**/
  GPIO_InitStruct.Pin = PHOTO_ADC_CS_Pin;
  GPIO_InitStruct.Mode = LL_GPIO_MODE_OUTPUT;
  GPIO_InitStruct.Speed = LL_GPIO_SPEED_FREQ_LOW;
  GPIO_InitStruct.OutputType = LL_GPIO_OUTPUT_PUSHPULL;
  GPIO_InitStruct.Pull = LL_GPIO_PULL_NO;
  LL_GPIO_Init(PHOTO_ADC_CS_GPIO_Port, &GPIO_InitStruct);

  /**/
  GPIO_InitStruct.Pin = LASER_EXT_SW_CS_Pin;
  GPIO_InitStruct.Mode = LL_GPIO_MODE_OUTPUT;
  GPIO_InitStruct.Speed = LL_GPIO_SPEED_FREQ_LOW;
  GPIO_InitStruct.OutputType = LL_GPIO_OUTPUT_PUSHPULL;
  GPIO_InitStruct.Pull = LL_GPIO_PULL_NO;
  LL_GPIO_Init(LASER_EXT_SW_CS_GPIO_Port, &GPIO_InitStruct);

  /**/
  GPIO_InitStruct.Pin = Log_OverFlow_Pin;
  GPIO_InitStruct.Mode = LL_GPIO_MODE_OUTPUT;
  GPIO_InitStruct.Speed = LL_GPIO_SPEED_FREQ_LOW;
  GPIO_InitStruct.OutputType = LL_GPIO_OUTPUT_PUSHPULL;
  GPIO_InitStruct.Pull = LL_GPIO_PULL_UP;
  LL_GPIO_Init(Log_OverFlow_GPIO_Port, &GPIO_InitStruct);

  /**/
  GPIO_InitStruct.Pin = MIN_HandShake_Pin;
  GPIO_InitStruct.Mode = LL_GPIO_MODE_OUTPUT;
  GPIO_InitStruct.Speed = LL_GPIO_SPEED_FREQ_LOW;
  GPIO_InitStruct.OutputType = LL_GPIO_OUTPUT_PUSHPULL;
  GPIO_InitStruct.Pull = LL_GPIO_PULL_DOWN;
  LL_GPIO_Init(MIN_HandShake_GPIO_Port, &GPIO_InitStruct);

  /**/
  GPIO_InitStruct.Pin = LASER_DAC_LATCH_Pin;
  GPIO_InitStruct.Mode = LL_GPIO_MODE_OUTPUT;
  GPIO_InitStruct.Speed = LL_GPIO_SPEED_FREQ_LOW;
  GPIO_InitStruct.OutputType = LL_GPIO_OUTPUT_PUSHPULL;
  GPIO_InitStruct.Pull = LL_GPIO_PULL_NO;
  LL_GPIO_Init(LASER_DAC_LATCH_GPIO_Port, &GPIO_InitStruct);

  /**/
  GPIO_InitStruct.Pin = PHOTO_SW_CS_Pin;
  GPIO_InitStruct.Mode = LL_GPIO_MODE_OUTPUT;
  GPIO_InitStruct.Speed = LL_GPIO_SPEED_FREQ_VERY_HIGH;
  GPIO_InitStruct.OutputType = LL_GPIO_OUTPUT_PUSHPULL;
  GPIO_InitStruct.Pull = LL_GPIO_PULL_NO;
  LL_GPIO_Init(PHOTO_SW_CS_GPIO_Port, &GPIO_InitStruct);

  /**/
  GPIO_InitStruct.Pin = WD_DONE_Pin;
  GPIO_InitStruct.Mode = LL_GPIO_MODE_OUTPUT;
  GPIO_InitStruct.Speed = LL_GPIO_SPEED_FREQ_VERY_HIGH;
  GPIO_InitStruct.OutputType = LL_GPIO_OUTPUT_PUSHPULL;
  GPIO_InitStruct.Pull = LL_GPIO_PULL_NO;
  LL_GPIO_Init(WD_DONE_GPIO_Port, &GPIO_InitStruct);

  /**/
  GPIO_InitStruct.Pin = EF_12_AUX_Pin;
  GPIO_InitStruct.Mode = LL_GPIO_MODE_INPUT;
  GPIO_InitStruct.Pull = LL_GPIO_PULL_NO;
  LL_GPIO_Init(EF_12_AUX_GPIO_Port, &GPIO_InitStruct);

  /**/
  GPIO_InitStruct.Pin = PHOTO_ADC_EOC_Pin;
  GPIO_InitStruct.Mode = LL_GPIO_MODE_INPUT;
  GPIO_InitStruct.Pull = LL_GPIO_PULL_NO;
  LL_GPIO_Init(PHOTO_ADC_EOC_GPIO_Port, &GPIO_InitStruct);

  /**/
  GPIO_InitStruct.Pin = CONS_TX_Pin;
  GPIO_InitStruct.Mode = LL_GPIO_MODE_ALTERNATE;
  GPIO_InitStruct.Speed = LL_GPIO_SPEED_FREQ_VERY_HIGH;
  GPIO_InitStruct.OutputType = LL_GPIO_OUTPUT_PUSHPULL;
  GPIO_InitStruct.Pull = LL_GPIO_PULL_NO;
  GPIO_InitStruct.Alternate = LL_GPIO_AF_8;
  LL_GPIO_Init(CONS_TX_GPIO_Port, &GPIO_InitStruct);

  /**/
  GPIO_InitStruct.Pin = CONS_RX_Pin;
  GPIO_InitStruct.Mode = LL_GPIO_MODE_ALTERNATE;
  GPIO_InitStruct.Speed = LL_GPIO_SPEED_FREQ_VERY_HIGH;
  GPIO_InitStruct.OutputType = LL_GPIO_OUTPUT_PUSHPULL;
  GPIO_InitStruct.Pull = LL_GPIO_PULL_NO;
  GPIO_InitStruct.Alternate = LL_GPIO_AF_8;
  LL_GPIO_Init(CONS_RX_GPIO_Port, &GPIO_InitStruct);

  /**/
  GPIO_InitStruct.Pin = IRQ_0_Pin;
  GPIO_InitStruct.Mode = LL_GPIO_MODE_OUTPUT;
  GPIO_InitStruct.Speed = LL_GPIO_SPEED_FREQ_LOW;
  GPIO_InitStruct.OutputType = LL_GPIO_OUTPUT_PUSHPULL;
  GPIO_InitStruct.Pull = LL_GPIO_PULL_UP;
  LL_GPIO_Init(IRQ_0_GPIO_Port, &GPIO_InitStruct);

  /**/
  GPIO_InitStruct.Pin = IRQ_1_Pin;
  GPIO_InitStruct.Mode = LL_GPIO_MODE_INPUT;
  GPIO_InitStruct.Pull = LL_GPIO_PULL_NO;
  LL_GPIO_Init(IRQ_1_GPIO_Port, &GPIO_InitStruct);

  /**/
  GPIO_InitStruct.Pin = PHOTO_ADC_CONV_Pin;
  GPIO_InitStruct.Mode = LL_GPIO_MODE_OUTPUT;
  GPIO_InitStruct.Speed = LL_GPIO_SPEED_FREQ_VERY_HIGH;
  GPIO_InitStruct.OutputType = LL_GPIO_OUTPUT_PUSHPULL;
  GPIO_InitStruct.Pull = LL_GPIO_PULL_NO;
  LL_GPIO_Init(PHOTO_ADC_CONV_GPIO_Port, &GPIO_InitStruct);

  /**/
  GPIO_InitStruct.Pin = LED_G_Pin;
  GPIO_InitStruct.Mode = LL_GPIO_MODE_OUTPUT;
  GPIO_InitStruct.Speed = LL_GPIO_SPEED_FREQ_LOW;
  GPIO_InitStruct.OutputType = LL_GPIO_OUTPUT_PUSHPULL;
  GPIO_InitStruct.Pull = LL_GPIO_PULL_NO;
  LL_GPIO_Init(LED_G_GPIO_Port, &GPIO_InitStruct);

  /**/
  GPIO_InitStruct.Pin = LED_B_Pin;
  GPIO_InitStruct.Mode = LL_GPIO_MODE_OUTPUT;
  GPIO_InitStruct.Speed = LL_GPIO_SPEED_FREQ_LOW;
  GPIO_InitStruct.OutputType = LL_GPIO_OUTPUT_PUSHPULL;
  GPIO_InitStruct.Pull = LL_GPIO_PULL_NO;
  LL_GPIO_Init(LED_B_GPIO_Port, &GPIO_InitStruct);

  /**/
  GPIO_InitStruct.Pin = ADG_MOSI_Pin;
  GPIO_InitStruct.Mode = LL_GPIO_MODE_OUTPUT;
  GPIO_InitStruct.Speed = LL_GPIO_SPEED_FREQ_LOW;
  GPIO_InitStruct.OutputType = LL_GPIO_OUTPUT_PUSHPULL;
  GPIO_InitStruct.Pull = LL_GPIO_PULL_NO;
  LL_GPIO_Init(ADG_MOSI_GPIO_Port, &GPIO_InitStruct);

  /**/
  GPIO_InitStruct.Pin = ADG_SCK_Pin;
  GPIO_InitStruct.Mode = LL_GPIO_MODE_OUTPUT;
  GPIO_InitStruct.Speed = LL_GPIO_SPEED_FREQ_LOW;
  GPIO_InitStruct.OutputType = LL_GPIO_OUTPUT_PUSHPULL;
  GPIO_InitStruct.Pull = LL_GPIO_PULL_NO;
  LL_GPIO_Init(ADG_SCK_GPIO_Port, &GPIO_InitStruct);

  /**/
  GPIO_InitStruct.Pin = ADG_CS_Pin;
  GPIO_InitStruct.Mode = LL_GPIO_MODE_OUTPUT;
  GPIO_InitStruct.Speed = LL_GPIO_SPEED_FREQ_LOW;
  GPIO_InitStruct.OutputType = LL_GPIO_OUTPUT_PUSHPULL;
  GPIO_InitStruct.Pull = LL_GPIO_PULL_NO;
  LL_GPIO_Init(ADG_CS_GPIO_Port, &GPIO_InitStruct);

  /**/
  GPIO_InitStruct.Pin = EF_5_AUX_Pin;
  GPIO_InitStruct.Mode = LL_GPIO_MODE_INPUT;
  GPIO_InitStruct.Pull = LL_GPIO_PULL_NO;
  LL_GPIO_Init(EF_5_AUX_GPIO_Port, &GPIO_InitStruct);

  /**/
  GPIO_InitStruct.Pin = EF_5_EN_Pin;
  GPIO_InitStruct.Mode = LL_GPIO_MODE_OUTPUT;
  GPIO_InitStruct.Speed = LL_GPIO_SPEED_FREQ_LOW;
  GPIO_InitStruct.OutputType = LL_GPIO_OUTPUT_PUSHPULL;
  GPIO_InitStruct.Pull = LL_GPIO_PULL_NO;
  LL_GPIO_Init(EF_5_EN_GPIO_Port, &GPIO_InitStruct);

  /**/
  GPIO_InitStruct.Pin = SENSOR1_EN_Pin;
  GPIO_InitStruct.Mode = LL_GPIO_MODE_OUTPUT;
  GPIO_InitStruct.Speed = LL_GPIO_SPEED_FREQ_LOW;
  GPIO_InitStruct.OutputType = LL_GPIO_OUTPUT_PUSHPULL;
  GPIO_InitStruct.Pull = LL_GPIO_PULL_NO;
  LL_GPIO_Init(SENSOR1_EN_GPIO_Port, &GPIO_InitStruct);

  /**/
  GPIO_InitStruct.Pin = SENSOR2_EN_Pin;
  GPIO_InitStruct.Mode = LL_GPIO_MODE_OUTPUT;
  GPIO_InitStruct.Speed = LL_GPIO_SPEED_FREQ_LOW;
  GPIO_InitStruct.OutputType = LL_GPIO_OUTPUT_PUSHPULL;
  GPIO_InitStruct.Pull = LL_GPIO_PULL_NO;
  LL_GPIO_Init(SENSOR2_EN_GPIO_Port, &GPIO_InitStruct);

  /**/
  GPIO_InitStruct.Pin = FRAM_CS_Pin;
  GPIO_InitStruct.Mode = LL_GPIO_MODE_OUTPUT;
  GPIO_InitStruct.Speed = LL_GPIO_SPEED_FREQ_LOW;
  GPIO_InitStruct.OutputType = LL_GPIO_OUTPUT_PUSHPULL;
  GPIO_InitStruct.Pull = LL_GPIO_PULL_NO;
  LL_GPIO_Init(FRAM_CS_GPIO_Port, &GPIO_InitStruct);

  /**/
  GPIO_InitStruct.Pin = TEC_4_CS_Pin;
  GPIO_InitStruct.Mode = LL_GPIO_MODE_OUTPUT;
  GPIO_InitStruct.Speed = LL_GPIO_SPEED_FREQ_LOW;
  GPIO_InitStruct.OutputType = LL_GPIO_OUTPUT_PUSHPULL;
  GPIO_InitStruct.Pull = LL_GPIO_PULL_NO;
  LL_GPIO_Init(TEC_4_CS_GPIO_Port, &GPIO_InitStruct);

  /**/
  GPIO_InitStruct.Pin = TEC_3_CS_Pin;
  GPIO_InitStruct.Mode = LL_GPIO_MODE_OUTPUT;
  GPIO_InitStruct.Speed = LL_GPIO_SPEED_FREQ_LOW;
  GPIO_InitStruct.OutputType = LL_GPIO_OUTPUT_PUSHPULL;
  GPIO_InitStruct.Pull = LL_GPIO_PULL_NO;
  LL_GPIO_Init(TEC_3_CS_GPIO_Port, &GPIO_InitStruct);

  /**/
  GPIO_InitStruct.Pin = TEC_2_CS_Pin;
  GPIO_InitStruct.Mode = LL_GPIO_MODE_OUTPUT;
  GPIO_InitStruct.Speed = LL_GPIO_SPEED_FREQ_LOW;
  GPIO_InitStruct.OutputType = LL_GPIO_OUTPUT_PUSHPULL;
  GPIO_InitStruct.Pull = LL_GPIO_PULL_NO;
  LL_GPIO_Init(TEC_2_CS_GPIO_Port, &GPIO_InitStruct);

  /**/
  GPIO_InitStruct.Pin = TEC_1_CS_Pin;
  GPIO_InitStruct.Mode = LL_GPIO_MODE_OUTPUT;
  GPIO_InitStruct.Speed = LL_GPIO_SPEED_FREQ_LOW;
  GPIO_InitStruct.OutputType = LL_GPIO_OUTPUT_PUSHPULL;
  GPIO_InitStruct.Pull = LL_GPIO_PULL_NO;
  LL_GPIO_Init(TEC_1_CS_GPIO_Port, &GPIO_InitStruct);

}

void Error_Handler(void)
{
  __disable_irq();
  while (1)
  {
  }
}
